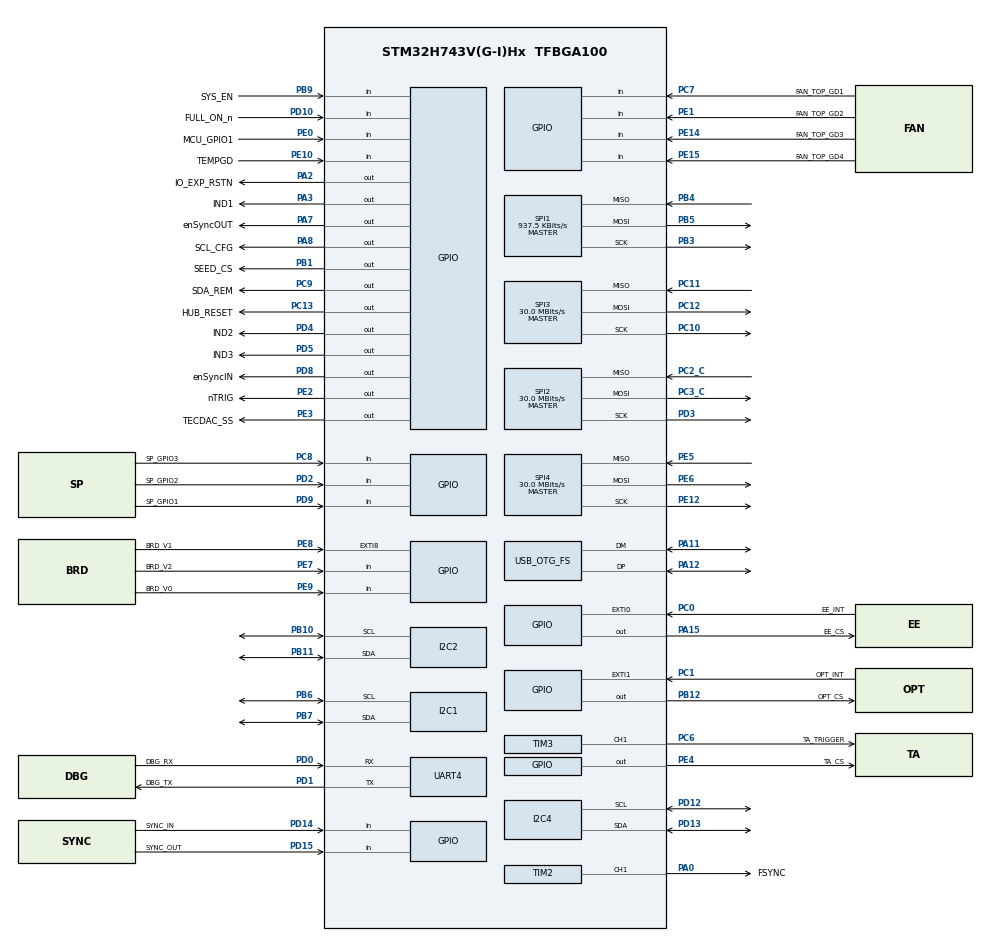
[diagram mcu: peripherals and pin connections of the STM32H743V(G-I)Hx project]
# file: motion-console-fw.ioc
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CORTEX_M7.default_mode_Activation=1
Dma.Request0=UART4_RX
Dma.Request1=UART4_TX
Dma.UART4_RX.0.Direction=DMA_PERIPH_TO_MEMORY
Dma.UART4_RX.0.EventEnable=DISABLE
Dma.UART4_RX.0.FIFOMode=DMA_FIFOMODE_DISABLE
Dma.UART4_RX.0.Instance=DMA1_Stream0
Dma.UART4_RX.0.MemDataAlignment=DMA_MDATAALIGN_BYTE
Dma.UART4_RX.0.MemInc=DMA_MINC_ENABLE
Dma.UART4_RX.0.Mode=DMA_NORMAL
Dma.UART4_RX.0.PeriphDataAlignment=DMA_PDATAALIGN_BYTE
Dma.UART4_RX.0.PeriphInc=DMA_PINC_DISABLE
Dma.UART4_RX.0.Polarity=HAL_DMAMUX_REQ_GEN_RISING
Dma.UART4_RX.0.Priority=DMA_PRIORITY_LOW
Dma.UART4_RX.0.RequestNumber=1
Dma.UART4_RX.0.SignalID=NONE
Dma.UART4_RX.0.SyncEnable=DISABLE
Dma.UART4_RX.0.SyncPolarity=HAL_DMAMUX_SYNC_NO_EVENT
Dma.UART4_RX.0.SyncRequestNumber=1
Dma.UART4_RX.0.SyncSignalID=NONE
Dma.UART4_TX.1.Direction=DMA_MEMORY_TO_PERIPH
Dma.UART4_TX.1.EventEnable=DISABLE
Dma.UART4_TX.1.FIFOMode=DMA_FIFOMODE_DISABLE
Dma.UART4_TX.1.Instance=DMA1_Stream1
Dma.UART4_TX.1.MemDataAlignment=DMA_MDATAALIGN_BYTE
Dma.UART4_TX.1.MemInc=DMA_MINC_ENABLE
Dma.UART4_TX.1.Mode=DMA_NORMAL
Dma.UART4_TX.1.PeriphDataAlignment=DMA_PDATAALIGN_BYTE
Dma.UART4_TX.1.PeriphInc=DMA_PINC_DISABLE
Dma.UART4_TX.1.Polarity=HAL_DMAMUX_REQ_GEN_RISING
Dma.UART4_TX.1.Priority=DMA_PRIORITY_LOW
Dma.UART4_TX.1.RequestNumber=1
Dma.UART4_TX.1.SignalID=NONE
Dma.UART4_TX.1.SyncEnable=DISABLE
Dma.UART4_TX.1.SyncPolarity=HAL_DMAMUX_SYNC_NO_EVENT
Dma.UART4_TX.1.SyncRequestNumber=1
Dma.UART4_TX.1.SyncSignalID=NONE
I2C1.Timing=0x10B71B27
I2C2.Timing=0x107075B0
I2C4.Timing=0x107075B0
Mcu.Family=STM32H7
Mcu.Name=STM32H743V(G-I)Hx
Mcu.Package=TFBGA100
NVIC.DMA1_Stream0_IRQn=true\:0\:0\:false\:false\:true\:false\:true\:true
NVIC.DMA1_Stream1_IRQn=true\:0\:0\:false\:false\:true\:false\:true\:true
NVIC.I2C1_ER_IRQn=true\:0\:0\:false\:false\:true\:true\:true\:true
NVIC.I2C1_EV_IRQn=true\:0\:0\:false\:false\:true\:true\:true\:true
NVIC.I2C2_ER_IRQn=true\:0\:0\:false\:false\:true\:true\:true\:true
NVIC.I2C2_EV_IRQn=true\:0\:0\:false\:false\:true\:true\:true\:true
NVIC.I2C4_ER_IRQn=true\:0\:0\:false\:false\:true\:true\:true\:true
NVIC.I2C4_EV_IRQn=true\:0\:0\:false\:false\:true\:true\:true\:true
NVIC.OTG_FS_IRQn=true\:0\:0\:false\:false\:true\:false\:true\:true
NVIC.PriorityGroup=NVIC_PRIORITYGROUP_4
NVIC.SPI1_IRQn=true\:0\:0\:false\:false\:true\:true\:true\:true
NVIC.TIM15_IRQn=true\:0\:0\:false\:false\:true\:true\:true\:true
NVIC.TIM17_IRQn=true\:15\:0\:false\:false\:true\:false\:true\:true
NVIC.TIM2_IRQn=true\:0\:0\:false\:false\:true\:true\:true\:true
NVIC.TIM3_IRQn=true\:0\:0\:false\:false\:true\:true\:true\:true
NVIC.TIM4_IRQn=true\:0\:0\:false\:false\:true\:true\:true\:true
NVIC.TIM8_BRK_TIM12_IRQn=true\:0\:0\:false\:false\:true\:true\:true\:true
NVIC.TIM8_CC_IRQn=true\:0\:0\:false\:false\:true\:true\:true\:true
NVIC.TIM8_TRG_COM_TIM14_IRQn=true\:0\:0\:false\:false\:true\:true\:true\:true
NVIC.TIM8_UP_TIM13_IRQn=true\:0\:0\:false\:false\:true\:true\:true\:true
NVIC.TimeBase=TIM17_IRQn
NVIC.TimeBaseIP=TIM17
NVIC.UART4_IRQn=true\:0\:0\:false\:false\:true\:true\:true\:true
PA0.GPIO_Label=FSYNC
PA0.Signal=S_TIM2_CH1_ETR
PA11.Mode=Device_Only
PA11.Signal=USB_OTG_FS_DM
PA12.Mode=Device_Only
PA12.Signal=USB_OTG_FS_DP
PA13\ (JTMS/SWDIO).Mode=Serial_Wire
PA13\ (JTMS/SWDIO).Signal=DEBUG_JTMS-SWDIO
PA14\ (JTCK/SWCLK).Mode=Serial_Wire
PA14\ (JTCK/SWCLK).Signal=DEBUG_JTCK-SWCLK
PA15\ (JTDI).GPIO_Label=EE_CS
PA15\ (JTDI).PinState=GPIO_PIN_SET
PA15\ (JTDI).Signal=GPIO_Output
PA2.GPIO_Label=IO_EXP_RSTN
PA2.PinState=GPIO_PIN_SET
PA2.Signal=GPIO_Output
PA3.GPIO_Label=IND1
PA3.PinState=GPIO_PIN_SET
PA3.Signal=GPIO_Output
PA7.GPIO_Label=enSyncOUT
PA7.PinState=GPIO_PIN_SET
PA7.Signal=GPIO_Output
PA8.GPIO_Label=SCL_CFG
PA8.Signal=GPIO_Output
PB1.GPIO_Label=SEED_CS
PB1.PinState=GPIO_PIN_SET
PB1.Signal=GPIO_Output
PB10.Mode=I2C
PB10.Signal=I2C2_SCL
PB11.Mode=I2C
PB11.Signal=I2C2_SDA
PB12.GPIO_Label=OPT_CS
PB12.PinState=GPIO_PIN_SET
PB12.Signal=GPIO_Output
PB3\ (JTDO/TRACESWO).Mode=Full_Duplex_Master
PB3\ (JTDO/TRACESWO).Signal=SPI1_SCK
PB4\ (NJTRST).Mode=Full_Duplex_Master
PB4\ (NJTRST).Signal=SPI1_MISO
PB5.Mode=Full_Duplex_Master
PB5.Signal=SPI1_MOSI
PB6.Mode=I2C
PB6.Signal=I2C1_SCL
PB7.Mode=I2C
PB7.Signal=I2C1_SDA
PB9.GPIO_Label=SYS_EN
PB9.Signal=GPIO_Input
PC0.GPIO_Label=EE_INT
PC0.Signal=GPXTI0
PC1.GPIO_Label=OPT_INT
PC1.Signal=GPXTI1
PC10.Mode=Full_Duplex_Master
PC10.Signal=SPI3_SCK
PC11.Mode=Full_Duplex_Master
PC11.Signal=SPI3_MISO
PC12.Mode=Full_Duplex_Master
PC12.Signal=SPI3_MOSI
PC13.GPIO_Label=HUB_RESET
PC13.Signal=GPIO_Output
PC2_C.Mode=Full_Duplex_Master
PC2_C.Signal=SPI2_MISO
PC3_C.Mode=Full_Duplex_Master
PC3_C.Signal=SPI2_MOSI
PC6.GPIO_Label=TA_TRIGGER
PC6.Signal=S_TIM3_CH1
PC7.GPIO_Label=FAN_TOP_GD1
PC7.Signal=GPIO_Input
PC8.GPIO_Label=SP_GPIO3
PC8.Signal=GPIO_Input
PC9.GPIO_Label=SDA_REM
PC9.Signal=GPIO_Output
PD0.GPIO_Label=DBG_RX
PD0.Mode=Asynchronous
PD0.Signal=UART4_RX
PD1.GPIO_Label=DBG_TX
PD1.Mode=Asynchronous
PD1.Signal=UART4_TX
PD10.GPIO_Label=FULL_ON_n
PD10.Signal=GPIO_Input
PD12.Mode=I2C
PD12.Signal=I2C4_SCL
PD13.Mode=I2C
PD13.Signal=I2C4_SDA
PD14.GPIO_Label=SYNC_IN
PD14.Signal=GPIO_Input
PD15.GPIO_Label=SYNC_OUT
PD15.Signal=GPIO_Input
PD2.GPIO_Label=SP_GPIO2
PD2.Signal=GPIO_Input
PD3.Mode=Full_Duplex_Master
PD3.Signal=SPI2_SCK
PD4.GPIO_Label=IND2
PD4.PinState=GPIO_PIN_SET
PD4.Signal=GPIO_Output
PD5.GPIO_Label=IND3
PD5.PinState=GPIO_PIN_SET
PD5.Signal=GPIO_Output
PD8.GPIO_Label=enSyncIN
PD8.Signal=GPIO_Output
PD9.GPIO_Label=SP_GPIO1
PD9.Signal=GPIO_Input
PE0.GPIO_Label=MCU_GPIO1
PE0.Signal=GPIO_Input
PE1.GPIO_Label=FAN_TOP_GD2
PE1.Signal=GPIO_Input
PE10.GPIO_Label=TEMPGD
PE10.Signal=GPIO_Input
PE12.Mode=Full_Duplex_Master
PE12.Signal=SPI4_SCK
PE14.GPIO_Label=FAN_TOP_GD3
PE14.Signal=GPIO_Input
PE15.GPIO_Label=FAN_TOP_GD4
PE15.Signal=GPIO_Input
PE2.GPIO_Label=nTRIG
PE2.PinState=GPIO_PIN_SET
PE2.Signal=GPIO_Output
PE3.GPIO_Label=TECDAC_SS
PE3.PinState=GPIO_PIN_SET
PE3.Signal=GPIO_Output
PE4.GPIO_Label=TA_CS
PE4.PinState=GPIO_PIN_SET
PE4.Signal=GPIO_Output
PE5.Mode=Full_Duplex_Master
PE5.Signal=SPI4_MISO
PE6.Mode=Full_Duplex_Master
PE6.Signal=SPI4_MOSI
PE7.GPIO_Label=BRD_V2
PE7.Signal=GPIO_Input
PE8.GPIO_Label=BRD_V1
PE8.Signal=GPXTI8
PE9.GPIO_Label=BRD_V0
PE9.Signal=GPIO_Input
PH0-OSC_IN\ (PH0).Mode=HSE-External-Oscillator
PH0-OSC_IN\ (PH0).Signal=RCC_OSC_IN
PH1-OSC_OUT\ (PH1).Mode=HSE-External-Oscillator
PH1-OSC_OUT\ (PH1).Signal=RCC_OSC_OUT
ProjectManager.HeapSize=0x200
ProjectManager.StackSize=0x400
ProjectManager.TargetToolchain=CMake
RCC.ADCFreq_Value=480000000
RCC.APB1Freq_Value=120000000
RCC.APB2Freq_Value=120000000
RCC.APB3Freq_Value=120000000
RCC.APB4Freq_Value=120000000
RCC.CortexFreq_Value=240000000
RCC.DIVM1=3
RCC.DIVM2=3
RCC.DIVM3=3
RCC.DIVN1=120
RCC.DIVN2=120
RCC.DIVN3=120
RCC.DIVP1=4
RCC.DIVQ1=16
RCC.DIVQ2=16
RCC.DIVQ3=16
RCC.DIVR1=16
RCC.DIVR3=16
RCC.HCLKFreq_Value=120000000
RCC.HPRE=RCC_HCLK_DIV2
RCC.HSE_VALUE=24000000
RCC.I2C123CLockSelection=RCC_I2C123CLKSOURCE_PLL3
RCC.I2C4CLockSelection=RCC_I2C4CLKSOURCE_PLL3
RCC.LPTIM1CLockSelection=RCC_LPTIM1CLKSOURCE_PLL3
RCC.PLLSourceVirtual=RCC_PLLSOURCE_HSE
RCC.RNGCLockSelection=RCC_RNGCLKSOURCE_PLL
RCC.SYSCLKFreq_VALUE=240000000
RCC.SYSCLKSource=RCC_SYSCLKSOURCE_PLLCLK
RCC.Spi45ClockSelection=RCC_SPI45CLKSOURCE_PLL2
RCC.USART234578CLockSelection=RCC_USART234578CLKSOURCE_PLL2
RCC.USBCLockSelection=RCC_USBCLKSOURCE_HSI48
RCC.USBFreq_Value=48000000
SH.S_TIM2_CH1_ETR.0=TIM2_CH1,PWM Generation1 CH1
SH.S_TIM3_CH1.0=TIM3_CH1,PWM Generation1 CH1
SPI1.BaudRatePrescaler=SPI_BAUDRATEPRESCALER_64
SPI1.CLKPhase=SPI_PHASE_2EDGE
SPI1.CalculateBaudRate=937.5 KBits/s
SPI1.DataSize=SPI_DATASIZE_8BIT
SPI1.Direction=SPI_DIRECTION_2LINES
SPI1.FirstBit=SPI_FIRSTBIT_MSB
SPI1.Mode=SPI_MODE_MASTER
SPI1.NSSPMode=SPI_NSS_PULSE_DISABLE
SPI1.VirtualType=VM_MASTER
SPI2.CalculateBaudRate=30.0 MBits/s
SPI2.Direction=SPI_DIRECTION_2LINES
SPI2.Mode=SPI_MODE_MASTER
SPI2.VirtualType=VM_MASTER
SPI3.CalculateBaudRate=30.0 MBits/s
SPI3.Direction=SPI_DIRECTION_2LINES
SPI3.Mode=SPI_MODE_MASTER
SPI3.VirtualType=VM_MASTER
SPI4.CalculateBaudRate=30.0 MBits/s
SPI4.Direction=SPI_DIRECTION_2LINES
SPI4.Mode=SPI_MODE_MASTER
SPI4.VirtualType=VM_MASTER
TIM12.Period=25000-1
TIM12.Prescaler=120-1
TIM15.Period=8000-1
TIM15.Prescaler=1200-1
TIM2.Channel-PWM\ Generation1\ CH1=TIM_CHANNEL_1
TIM2.Period=25000-1
TIM2.Prescaler=120-1
TIM2.Pulse-PWM\ Generation1\ CH1=1000
TIM2.TIM_MasterOutputTrigger=TIM_TRGO_UPDATE
TIM3.Channel-PWM\ Generation1\ CH1=TIM_CHANNEL_1
TIM3.OCPolarity_1=TIM_OCPOLARITY_LOW
TIM3.Period=1250-1
TIM3.Prescaler=120-1
TIM3.Pulse-PWM\ Generation1\ CH1=250
TIM4.Period=2500-1
TIM4.Prescaler=12000-1
TIM8.Period=2500-1
TIM8.Prescaler=12000-1
USB_DEVICE.CLASS_NAME_FS=CDC
USB_DEVICE.PID_CDC_FS=0xA53E
USB_DEVICE.VID-CDC_FS=0x483
USB_DEVICE.VirtualMode-CDC_FS=Cdc
USB_DEVICE.VirtualModeFS=Cdc_FS
USB_OTG_FS.VirtualMode=Device_Only
VP_CRC_VS_CRC.Mode=CRC_Activate
VP_IWDG1_VS_IWDG.Mode=IWDG_Activate
VP_MEMORYMAP_VS_MEMORYMAP.Mode=CurAppReg
VP_RNG_VS_RNG.Mode=RNG_Activate
VP_SYS_VS_tim17.Mode=TIM17
VP_TIM12_VS_ClockSourceINT.Mode=Internal
VP_TIM15_VS_ClockSourceINT.Mode=Internal
VP_TIM1_VS_ClockSourceINT.Mode=Internal
VP_TIM2_VS_ClockSourceINT.Mode=Internal
VP_TIM3_VS_ClockSourceINT.Mode=Internal
VP_TIM3_VS_ClockSourceITR.Mode=TriggerSource_ITR1
VP_TIM3_VS_ControllerModeTrigger.Mode=Trigger Mode
VP_TIM3_VS_OPM.Mode=OPM_bit
VP_TIM4_VS_ClockSourceINT.Mode=Internal
VP_TIM8_VS_ClockSourceINT.Mode=Internal
VP_USB_DEVICE_VS_USB_DEVICE_CDC_FS.Mode=CDC_FS
board=custom

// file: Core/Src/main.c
/* USER CODE BEGIN Header */
/**
  ******************************************************************************
  * @file           : main.c
  * @brief          : Main program body
  ******************************************************************************
  * @attention
  *
  * Copyright (c) 2025 STMicroelectronics.
  * All rights reserved.
  *
  * This software is licensed under terms that can be found in the LICENSE file
  * in the root directory of this software component.
  * If no LICENSE file comes with this software, it is provided AS-IS.
  *
  ******************************************************************************
  */
 #include "version.h"
/* USER CODE END Header */
#include "main.h"
#include "usb_device.h"

/* USER CODE BEGIN Includes */
#include "usb_recovery.h"
#include "logging.h"
#include "usbd_cdc_if.h"
#include "uart_comms.h"
#include "trigger.h"
#include "pdc_poll.h"
#include "led_driver.h"
#include "tca9548a.h"
#include "console_i2c_health.h"
#include "pca9535.h"
#include "ads7828.h"
#include "ads7924.h"
#include "fan_driver.h"
#include "ad5761r.h"
#include "XO2_dev.h"
#include "XO2_api.h"
#include "XO2_cmds.h"
#include "fpga_attest.h"
#include "safety_envelope.h"
#include "safety_ufm_record.h"
#include "motion_cfg_keys.h"

/* Bus time per main-loop iteration given to the FPGA attestation readback
 * (about 5 configuration pages at 100 kHz). Keeps command latency and the
 * 25 ms telemetry cadence within their budgets while the check runs. */
#define FPGA_ATTEST_BUDGET_MS 12U
#include "if_fpga_prog.h"
#include "motion_config.h"
#include "fpga_register_map.h"
#include "jsmn.h"
#include "utils.h"
#include "msg_queue.h"
#include "odometer.h"
#include "console_serial.h"

#include <stdio.h>
#include <string.h>
#include <stdbool.h>
#include <stdlib.h>

/* USER CODE END Includes */

/* USER CODE BEGIN PD */

// #define SCAN_DISPLAY

/* USER CODE END PD */

CRC_HandleTypeDef hcrc;

I2C_HandleTypeDef hi2c1;
I2C_HandleTypeDef hi2c2;
I2C_HandleTypeDef hi2c4;

IWDG_HandleTypeDef hiwdg1;

RNG_HandleTypeDef hrng;

SPI_HandleTypeDef hspi1;
SPI_HandleTypeDef hspi2;
SPI_HandleTypeDef hspi3;
SPI_HandleTypeDef hspi4;

TIM_HandleTypeDef htim1;
TIM_HandleTypeDef htim2;
TIM_HandleTypeDef htim3;
TIM_HandleTypeDef htim4;
TIM_HandleTypeDef htim8;
TIM_HandleTypeDef htim12;
TIM_HandleTypeDef htim15;

UART_HandleTypeDef huart4;
DMA_HandleTypeDef hdma_uart4_rx;
DMA_HandleTypeDef hdma_uart4_tx;

/* USER CODE BEGIN PV */

uint8_t rxBuffer[COMMAND_MAX_SIZE];
uint8_t txBuffer[COMMAND_MAX_SIZE];

// Declare handles for your two multiplexers
extern TCA9548A_HandleTypeDef iic_mux[2];
extern ADS7828_HandleTypeDef adc_mon[2];
ADS7924_HandleTypeDef tec_ads;
extern bool ad5761r_enabled;
extern FAN_Driver fan;
static MachXO_Handle_t s_xo2_i2c_handle;
static XO2Handle_t     s_xo2_handle;

double TEC_TRIP_VALUE = 0.0;
double OPT_GAIN_VALUE = 0.0;
uint16_t OPT_THRESH_VALUE = 0;
double EE_GAIN_VALUE = 0.0;
uint16_t EE_THRESH_VALUE = 0;

ad5761r_dev tec_dac;

volatile bool _enter_dfu = false;

/* USER CODE END PV */

void SystemClock_Config(void);
void PeriphCommonClock_Config(void);
static void MPU_Config(void);
static void MX_GPIO_Init(void);
static void MX_DMA_Init(void);
static void MX_CRC_Init(void);
static void MX_I2C1_Init(void);
static void MX_I2C2_Init(void);
static void MX_RNG_Init(void);
static void MX_UART4_Init(void);
static void MX_TIM1_Init(void);
static void MX_TIM3_Init(void);
static void MX_TIM12_Init(void);
static void MX_TIM15_Init(void);
static void MX_I2C4_Init(void);
static void MX_TIM2_Init(void);
static void MX_SPI1_Init(void);
static void MX_SPI2_Init(void);
static void MX_SPI3_Init(void);
static void MX_SPI4_Init(void);
static void MX_TIM8_Init(void);
static void MX_TIM4_Init(void);
static void MX_IWDG1_Init(void);
/* USER CODE BEGIN PFP */

#ifdef SCAN_DISPLAY
static uint8_t I2C_scan(I2C_HandleTypeDef * pI2c, uint8_t* addr_list, size_t list_size, bool display) {

	uint8_t found = 0;

    // Iterate through all possible 7-bit addresses
    for (uint8_t address = 0x00; address <= 0x7F; address++) {
        HAL_StatusTypeDef status;
        watchdog_refresh(); /* up to 128 x 50 ms on a stuck bus */
        status = HAL_I2C_IsDeviceReady(pI2c, address << 1, 2, 50); // Address shift left by 1 for read/write bit
        if (status == HAL_OK) {
        	if(addr_list != NULL && found < list_size) {
        		addr_list[found] = address;
        	}
        	found++;
        	if(display)
        	{
        		printf("%2x ", address);
        	}
        }else{
        	if(display)
        	{
        		printf("-- ");
        	}
        }
        if (display && (address + 1) % 16 == 0)  printf("\r\n");
    }

	if(display)
	{
		printf("\r\n");
	    fflush(stdout);
	}

    return found;
}
#endif

/*
 * Clear the bootloader's failsafe boot counter (RTC->BKP6R).
 * The secure bootloader increments BKP6R on every launch attempt and arms the
 * IWDG before jumping here; after BL_BOOT_FAIL_MAX consecutive attempts that do
 * not clear it, the bootloader enters USB DFU instead of launching us. Calling
 * this once we have fully initialized signals a successful boot, so the next
 * normal reset starts from a clean count.
 *
 * The HAL RTC module is not enabled in this build, so access the backup domain
 * directly via CMSIS (same sequence used for the DFU request in main()'s loop).
 */
static void clear_boot_counter(void)
{
  PWR->CR1     |= PWR_CR1_DBP;            /* disable backup-domain write protect  */
  RCC->APB4ENR |= RCC_APB4ENR_RTCAPBEN;  /* RTC register APB interface clock      */
  RCC->CSR     |= RCC_CSR_LSION;          /* LSI on (RTC kernel clock source)      */
  { uint32_t to = 0U;
    while (((RCC->CSR & RCC_CSR_LSIRDY) == 0U) && (++to < 0x00100000U)) { } }
  if ((RCC->BDCR & RCC_BDCR_RTCSEL) == 0U) {
    RCC->BDCR = (RCC->BDCR & ~RCC_BDCR_RTCSEL) | RCC_BDCR_RTCSEL_1; /* LSI */
  }
  RCC->BDCR |= RCC_BDCR_RTCEN;            /* enable RTC                            */
  RTC->BKP6R = 0U;                        /* successful boot: reset the attempt count */
  __DSB();
}

void configure_pin_as_gpio_output(GPIO_TypeDef* GPIOx, uint16_t GPIO_Pin) {
    GPIO_InitTypeDef GPIO_InitStruct = {0};

    // 1. Enable the GPIO clock
    if (GPIOx == GPIOA) __HAL_RCC_GPIOA_CLK_ENABLE();
    else if (GPIOx == GPIOB) __HAL_RCC_GPIOB_CLK_ENABLE();
    else if (GPIOx == GPIOC) __HAL_RCC_GPIOC_CLK_ENABLE();
    // Add other GPIO ports as needed

    // 2. Configure the pin
    GPIO_InitStruct.Pin = GPIO_Pin;
    GPIO_InitStruct.Mode = GPIO_MODE_OUTPUT_PP;  // Push-pull output
    // GPIO_InitStruct.Mode = GPIO_MODE_OUTPUT_OD; // For open-drain output
    GPIO_InitStruct.Pull = GPIO_NOPULL;          // No pull-up or pull-down
    GPIO_InitStruct.Speed = GPIO_SPEED_FREQ_LOW; // Or MEDIUM/HIGH/VERY_HIGH

    HAL_GPIO_Init(GPIOx, &GPIO_InitStruct);
}

void delay_ms(uint32_t ms)
{
    uint32_t delay_cycles = (SystemCoreClock / 1000) * ms;
    while (delay_cycles--) {
        __NOP();  // Ensures the loop doesn't get optimized away
    }
}

/* Refresh the independent watchdog (250 ms window, CFW-01). A no-op before
 * MX_IWDG1_Init(). Call it only from bounded waits; Error_Handler() and the
 * fault handlers must never refresh it. */
void watchdog_refresh(void)
{
    if (hiwdg1.Instance != NULL) {
        (void)HAL_IWDG_Refresh(&hiwdg1);
    }
}

/* HAL_Delay() that keeps the watchdog refreshed, for the boot delays and the
 * FPGA programming waits (XO2 erase takes seconds). */
void delay_ms_wdg(uint32_t ms)
{
    uint32_t start = HAL_GetTick();

    watchdog_refresh();
    while ((HAL_GetTick() - start) < ms) {
        HAL_Delay(1);
        watchdog_refresh();
    }
}

/* USER CODE END PFP */

/* USER CODE BEGIN 0 */

/* ---- Safety parameters and the laser operating point --------------------
 * (PTR-2026-1-5 host-writable safety state; CFW-10; SDD ARCH-125/ARCH-83)
 *
 * Two kinds of register load, in this order, at boot, after every host
 * configuration write and after every completed FPGA attestation:
 *
 *   1. The SAFETY LOADS: the EE/OPT limit registers from the per-unit
 *      safety record in each safety FPGA's UFM (safety_ufm_record.h, bounded
 *      by safety_envelope.h), and the fixed TA / seed driver clamps of
 *      safety_envelope.h. No host data takes part. A device without a valid
 *      record gets no limit loads: its registers keep the design reset
 *      values, and the attestation interlock keeps the laser off.
 *   2. The OPERATIONAL point from the stored configuration record:
 *      TA_CURRENT_DRV, TA_PULSE_WIDTH, SEED_CW_GAIN, SEED_DDS_GAIN, each
 *      range-checked against the envelope; TA_PULSE_WIDTH is also lowered by
 *      the unit's record (motion_cfg_set_unit_ceiling: the ceiling applies to host config
 *      writes and to the I2C pass-through). Safety keys and unknown keys in
 *      the record are ignored and logged (they cannot be stored by this
 *      firmware; see motion_config.c).
 *
 * Every register is written and read back. Any failure is reported to the
 * host and refuses Trigger_Start() (TRIG_INTERLOCK_LIMITS) until a later
 * apply succeeds. The SDK used to write the same registers at connection
 * through OW_CTRL_I2C_WR; in a Release build those writes are now refused
 * for the safety-owned registers (fpga_register_map.c). */

static bool     s_limits_fault;
static unsigned s_limits_fail_count;
static char     s_limits_first_fail[56];

bool motion_cfg_limits_fault(void)
{
    return s_limits_fault;
}

static void limits_fail(const char *key, const char *why)
{
    printf("ERROR: %s not applied: %s\r\n", key, why);
    if (s_limits_fail_count == 0U) {
        (void)snprintf(s_limits_first_fail, sizeof(s_limits_first_fail), "%s: %s", key, why);
    }
    s_limits_fail_count++;
    s_limits_fault = true;
}

/* Write a register and read it back; NULL on success, else the reason. */
static const char *fpga_write_verify(const FpgaRegister *reg, const uint8_t *data)
{
    uint8_t rb[4] = {0, 0, 0, 0};

    if (TCA9548A_Write_Data(reg->muxIdx, reg->channel, reg->i2cAddr,
                            reg->offset, reg->data_len, (uint8_t *)data) != TCA9548A_OK) {
        return "write failed";
    }
    if (TCA9548A_Read_Data(reg->muxIdx, reg->channel, reg->i2cAddr,
                           reg->offset, reg->data_len, rb) != TCA9548A_OK) {
        return "read-back failed";
    }
    if (memcmp(rb, data, reg->data_len) != 0) {
        return "read-back mismatch";
    }
    return NULL;
}

/* Write a raw little-endian register value and read it back. */
static bool fpga_write_raw(const char *name, uint32_t raw)
{
    const FpgaRegister *reg = fpga_register_lookup(name);
    if (reg == NULL || reg->direction != FPGA_DIR_RW || reg->data_len == 0U || reg->data_len > 4U) {
        limits_fail(name, "not a settable register");
        return false;
    }
    if (reg->data_len < 4U && raw > ((1UL << (8U * reg->data_len)) - 1UL)) {
        limits_fail(name, "too large for the register");
        return false;
    }
    uint8_t data_buf[4] = {0, 0, 0, 0};
    for (uint8_t b = 0; b < reg->data_len; b++) {
        data_buf[b] = (uint8_t)((raw >> (8u * b)) & 0xFFu);
    }
    const char *why = fpga_write_verify(reg, data_buf);
    if (why != NULL) {
        limits_fail(name, why);
        return false;
    }
    return true;
}

/* 1. The safety loads (see above), and the unit's ceilings for the
 *    operating point. */
static void apply_safety_loads(void)
{
    const safety_ufm_limits_t *ee  = fpga_attest_ufm_limits((uint8_t)MUX_FPGA_SAFE_EE);
    const safety_ufm_limits_t *opt = fpga_attest_ufm_limits((uint8_t)MUX_FPGA_SAFE_OPT);
    safety_reg_load_t loads[SAFETY_REG_LOADS_MAX];
    size_t n = safety_reg_loads(ee, opt, loads, SAFETY_REG_LOADS_MAX);

    if (ee == NULL || opt == NULL) {
#if defined(OW_FACTORY_PROGRAMMING)
        printf("Safety record: EE %s, OPT %s; a device without one keeps its design limits until the stored configuration's safety keys override them (Factory image)\r\n",
               ee ? "valid" : "none", opt ? "valid" : "none");
#else
        printf("Safety record: EE %s, OPT %s; a device without one keeps its design limits and the laser stays interlocked\r\n",
               ee ? "valid" : "none", opt ? "valid" : "none");
#endif
    }
    motion_cfg_set_unit_ceiling("TA_PULSE_WIDTH", safety_ta_pulse_width_max_us(ee, opt));
    for (size_t i = 0; i < n; i++) {
        if (fpga_write_raw(loads[i].reg, loads[i].raw)) {
            printf("Safety %s -> raw=0x%08lX, verified%s\r\n", loads[i].reg,
                   (unsigned long)loads[i].raw, loads[i].per_unit ? " (per-unit record)" : "");
        }
    }
}

/* Read a little-endian register of up to 4 bytes through the register map. */
static bool fpga_read_u32(const char *key, uint32_t *out)
{
    const FpgaRegister *reg = fpga_register_lookup(key);
    uint8_t b[4] = {0, 0, 0, 0};

    if (reg == NULL || reg->data_len > 4U ||
        TCA9548A_Read_Data(reg->muxIdx, reg->channel, reg->i2cAddr, reg->offset,
                           reg->data_len, b) != TCA9548A_OK) {
        return false;
    }
    *out = (uint32_t)b[0] | ((uint32_t)b[1] << 8) | ((uint32_t)b[2] << 16) | ((uint32_t)b[3] << 24);
    return true;
}

/* The pulse-width lower limit must not exceed the upper limit. */
static void check_pulse_width_order(const char *ll_key, const char *ul_key)
{
    uint32_t ll = 0U, ul = 0U;

    if (!fpga_read_u32(ll_key, &ll) || !fpga_read_u32(ul_key, &ul)) {
        limits_fail(ul_key, "read-back failed");
    } else if (ll > ul) {
        limits_fail(ll_key, "above the upper limit");
    }
}

/* After an apply: report a limits fault to the host and stop a running
 * trigger. Trigger_Start() refuses while it is set. */
static void report_limits_state(void)
{
    if (!s_limits_fault) {
        return;
    }
    char m[MQ_MAX_MSG_SIZE];
    /* Compact so the longest key + reason still fits one queue slot
     * (MQ_MAX_MSG_SIZE); the first failure is named, the count covers all. */
    int n = snprintf(m, sizeof(m),
                     "{\"type\":\"system\",\"state\":\"error\",\"msg\":\"safety limit not applied\",\"key\":\"%.40s\",\"count\":%u}",
                     s_limits_first_fail, s_limits_fail_count);
    if (n > 0 && (size_t)n < sizeof(m)) {
        (void)mq_push(m, (size_t)n);
    }
    (void)Trigger_Stop();
}

/* TEC thermal trip threshold, from a temperature in degrees C. No logging:
 * it runs before the UART exists (see safety_envelope_init). */
static double s_tec_trip_c;
static void tec_trip_set_c(double trip_c)
{
    s_tec_trip_c = trip_c;
    TEC_TRIP_VALUE = solve_v(temperature_to_resistance(trip_c));
}

/* The compile-time safety parameters, in force from reset: called first
 * thing in main(), before any peripheral and before the configuration
 * record is read, so the thermal trip is armed whatever the record holds.
 * Nothing here may print or touch a peripheral: _write() on the
 * uninitialised debug UART ends in Error_Handler(). */
static void safety_envelope_init(void)
{
    tec_trip_set_c(SAFETY_TEC_TRIP_C);
}

/* 2. One operational key of the stored record. */
static void apply_operational_setting(const cfg_key_rule_t *rule, const char *keybuf, double val)
{
    double min = rule->min;
    double max = motion_cfg_effective_max(rule);   /* lowered by the unit's record (apply_safety_loads) */
    if (!isfinite(val) || val < min || val > max) {
        limits_fail(keybuf, "out of range");
        return;
    }
    if (rule->reg == NULL) {
        return;
    }
    uint32_t raw = safety_eng_to_raw(rule->reg, val);
    if (fpga_write_raw(rule->reg, raw)) {
        printf("Wrote %s -> raw=0x%08lX, verified\r\n", keybuf, (unsigned long)raw);
    }
}

#if defined(OW_FACTORY_PROGRAMMING)
/* Factory build only: a safety key in the stored record overrides the
 * firmware value, within the hard bounds, for bench and calibration work.
 * Applied after the safety loads, so it wins. */
static void apply_factory_override(const cfg_key_rule_t *rule, const char *keybuf, double val)
{
    if (!isfinite(val) || val < rule->min || val > rule->max) {
        limits_fail(keybuf, "override out of bounds");
        return;
    }
    printf("FACTORY override %s = %.3f\r\n", keybuf, val);
    if (strcmp(keybuf, "TEC_TRIP") == 0) {
        tec_trip_set_c(val);
    } else if (rule->reg != NULL) {
        (void)fpga_write_raw(rule->reg, safety_eng_to_raw(rule->reg, val));
    }
}
#endif

/* Copy one token's text into dst (NUL-terminated, truncated to fit). */
static void cfg_copy_token(char *dst, size_t dst_size, const char *json, const jsmntok_t *t)
{
    int len = t->end - t->start;
    int copy_len = (len < (int)dst_size - 1) ? len : (int)dst_size - 1;

    memcpy(dst, json + t->start, (size_t)copy_len);
    dst[copy_len] = '\0';
}

/* Apply one "key": value pair of the stored record by its class. */
static void cfg_apply_pair(const char *json, const jsmntok_t *key, const jsmntok_t *val)
{
    char keybuf[40];
    cfg_copy_token(keybuf, sizeof(keybuf), json, key);

    const cfg_key_rule_t *rule = motion_cfg_key_rule(keybuf);
    if (rule == NULL) {
        printf("%s: unknown key in the stored config, ignored\r\n", keybuf);
        return;
    }
    if (rule->cls == CFG_KEY_OPAQUE) {
        return;
    }
    double v = 0.0;
    bool is_number = motion_cfg_token_number(json, val, &v);
    if (rule->cls == CFG_KEY_SAFETY) {
#if defined(OW_FACTORY_PROGRAMMING)
        if (is_number) {
            apply_factory_override(rule, keybuf, v);
        } else {
            limits_fail(keybuf, "not a number");
        }
#else
        printf("%s: safety parameter in the stored config ignored (firmware-owned)\r\n", keybuf);
#endif
        return;
    }
    if (!is_number) {
        limits_fail(keybuf, "not a number");
        return;
    }
    apply_operational_setting(rule, keybuf, v);
}

void motion_cfg_apply_settings(void)
{
    const char *json_str = motion_cfg_get_json_ptr();
    if (json_str == NULL) { return; }

    jsmn_parser parser;
    /* Static (not on the stack): the token pool is sized for a full config and
     * is too large to put on the stack of a boot-path function. This routine is
     * only ever called from the single-threaded main loop / command handler. */
    static jsmntok_t tokens[MOTION_CFG_MAX_JSON_TOKENS];
    const unsigned int ntok = (unsigned int)(sizeof(tokens) / sizeof(tokens[0]));

    s_limits_fault = false;
    s_limits_fail_count = 0U;
    s_limits_first_fail[0] = '\0';

    /* 1. Firmware-owned limits first, whatever the record holds. */
    printf("TEC_TRIP %.1f C -> %.3f V (compiled in, in force since reset)\r\n", s_tec_trip_c, TEC_TRIP_VALUE);
    apply_safety_loads();

    /* 2. The operating point from the record. */
    jsmn_init(&parser, NULL);
    int r = jsmn_parse(&parser, json_str, strlen(json_str), tokens, ntok, NULL);
    if (r < 1 || tokens[0].type != JSMN_OBJECT) {
        printf("ERROR: motion config JSON parse failed (jsmn %d); operating point NOT applied\r\n", r);
        const char *msg = "{\"type\": \"system\", \"state\": \"error\", \"msg\": \"motion config parse failed; operating point not applied\"}";
        (void)mq_push(msg, strlen(msg));
        s_limits_fault = true;
    } else {
        int i = 1;
        for (int k = 0; k < tokens[0].size && i + 1 < r; k++) {
            if (tokens[i].type != JSMN_STRING) { break; }
            cfg_apply_pair(json_str, &tokens[i], &tokens[i + 1]);
            i = motion_cfg_skip_token(tokens, r, i + 1);
        }
    }

    check_pulse_width_order("EE_PULSE_WIDTH_LL", "EE_PULSE_WIDTH_UL");
    check_pulse_width_order("OPT_PULSE_WIDTH_LL", "OPT_PULSE_WIDTH_UL");
    report_limits_state();
}

/* USER CODE END 0 */

int main(void)
{

  /* USER CODE BEGIN 1 */
  /* The compile-time safety parameters are in force before anything else
   * runs: the TEC thermal trip threshold no longer depends on the stored
   * configuration record (safety_envelope.h). */
  safety_envelope_init();
  /* USER CODE END 1 */

  /* MPU Configuration--------------------------------------------------------*/
  MPU_Config();

  /* MCU Configuration--------------------------------------------------------*/

  /* Reset of all peripherals, Initializes the Flash interface and the Systick. */
  HAL_Init();

  /* Configure the system clock */
  SystemClock_Config();

  /* Configure the peripherals common clocks */
  PeriphCommonClock_Config();

  /* Initialize all configured peripherals */
  MX_GPIO_Init();
  MX_DMA_Init();
  MX_CRC_Init();
  MX_I2C1_Init();
  MX_I2C2_Init();
  MX_RNG_Init();
  MX_UART4_Init();
  MX_TIM1_Init();
  MX_TIM3_Init();
  MX_TIM12_Init();
  MX_TIM15_Init();
  MX_I2C4_Init();
  MX_TIM2_Init();
  MX_SPI1_Init();
  MX_SPI2_Init();
  MX_SPI3_Init();
  MX_SPI4_Init();
  MX_TIM8_Init();
  MX_TIM4_Init();
  MX_IWDG1_Init();
  /* USER CODE BEGIN 2 */

#if !defined(DEBUG) && !defined(BARE_METAL_BUILD)
  /* Debug port stays closed (PTR-2026-1-5 CON-02, CVE-1191). The secure bootloader
   * reconfigures PA13/PA14 (SWDIO/SWCLK) as plain inputs before launching us (DAP
   * lock). Nothing in this application touches those pins, but assert the state
   * here too so that a bootloader without the lock, or a future GPIO change, can
   * never leave the probe interface live on a Release unit. Analog mode: no
   * input buffer, no pull, lowest leakage. Debug builds keep SWD for development;
   * bare-metal builds have no bootloader in front of them and are not fielded. */
  {
    GPIO_InitTypeDef swd = {0};
    __HAL_RCC_GPIOA_CLK_ENABLE();
    swd.Pin  = GPIO_PIN_13 | GPIO_PIN_14;
    swd.Mode = GPIO_MODE_ANALOG;
    swd.Pull = GPIO_NOPULL;
    HAL_GPIO_Init(GPIOA, &swd);
  }
#endif

  init_dma_logging();

  DWT_Init();

  //HAL_GPIO_DeInit(SCL_CFG_GPIO_Port, SCL_CFG_Pin);
  //HAL_GPIO_DeInit(SDA_REM_GPIO_Port, SDA_REM_Pin);
  HAL_GPIO_WritePin(SCL_CFG_GPIO_Port, SCL_CFG_Pin, GPIO_PIN_RESET);
  HAL_GPIO_WritePin(SDA_REM_GPIO_Port, SDA_REM_Pin, GPIO_PIN_RESET);

  HAL_GPIO_WritePin(IO_EXP_RSTN_GPIO_Port, IO_EXP_RSTN_Pin, GPIO_PIN_RESET);
  HAL_GPIO_WritePin(HUB_RESET_GPIO_Port, HUB_RESET_Pin, GPIO_PIN_RESET);

  // HAL_GPIO_WritePin(SYS_EN_GPIO_Port, SYS_EN_Pin, GPIO_PIN_RESET);

  printf("\033c");
  delay_ms_wdg(250);
  printf("Openwater open-MOTION Console\r\n\r\n");
  printf("FW: %s (%s)\r\nDate: %s\r\n",
       FW_VERSION_STRING,
       FW_SHA_STRING,
       FW_BUILD_TIME_STRING);
  printf("Board Version: 0x%02X\r\n\r\n", BoardV_Read());
#if defined(OW_FACTORY_PROGRAMMING)
  printf("*** FACTORY BUILD: FPGA/UFM programming and safety-parameter overrides are ENABLED.\r\n"
         "*** Manufacturing and RMA bench use only. Not a clinical image.\r\n\r\n");
#endif
  printf("CPU Clock Frequency: %lu MHz\r\n", HAL_RCC_GetSysClockFreq() / 1000000);
  printf("Initializing, please wait ...\r\n");

  // setup fpga the XO2 I2C handle used for FPGA programming
  s_xo2_i2c_handle.hi2c    = &hi2c1;
  s_xo2_i2c_handle.verbose = 0;
  s_xo2_i2c_handle.addr7   = MACHXO_I2C_ADDR_7BIT;
  s_xo2_i2c_handle.mux_idx  = 0;
  s_xo2_i2c_handle.mux_ch  = MUX_FPGA_SEED;

  s_xo2_handle.cfgEn         = TRUE;
  s_xo2_handle.devType       = MachXO2_2000;
  s_xo2_handle.pI2CDrvrCalls = &s_xo2_i2c_handle;
  s_xo2_handle.pfuSecDelay   = delay_us;   /* microsecond delay */
  s_xo2_handle.pfmSecDelay   = delay_ms_wdg; /* millisecond delay; keeps the watchdog refreshed */

  /* Register the handle with the command interface for page-by-page programming */
  if_cmd_set_xo2_prog_handle(&s_xo2_handle);

  // configure TEC DAC
  printf("Initialize TEC DAC\r\n");
  tec_dac.hspi = &hspi1;
  tec_dac.cs_port = TECDAC_SS_GPIO_Port;
  tec_dac.cs_pin = TECDAC_SS_Pin;
  tec_dac.ldac_port=NULL;
  tec_dac.ldac_pin=0;
  tec_dac.clr_port=NULL;
  tec_dac.clr_pin=0;
  tec_dac.rst_port=NULL;
  tec_dac.rst_pin=0;
  tec_dac.type=AD5761R,
  tec_dac.ra=AD5761R_RANGE_M_5V_TO_P_5V;
  tec_dac.pv=AD5761R_SCALE_FULL;
  tec_dac.cv=AD5761R_SCALE_FULL;
  tec_dac.int_ref_en=true;
  tec_dac.exc_temp_sd_en=true;
  tec_dac.b2c_range_en=false;
  tec_dac.ovr_en=false;
  tec_dac.daisy_chain_en=false;

  if(ad5761r_init(&tec_dac) != HAL_OK){
	  printf("Failed to initialize TEC DAC\r\n");
  } else {
	uint16_t val = 0;
	val = volts_to_code(&tec_dac, 0.0f);
    if(ad5761r_write_update_dac_register(&tec_dac, val)){
		printf("TEC DAC Failed to set DAC Voltage\r\n");
	}else{
		printf("TEC DAC Initialized and set DAC Voltage\r\n");
    }
  }

  HAL_GPIO_WritePin(IO_EXP_RSTN_GPIO_Port, IO_EXP_RSTN_Pin, GPIO_PIN_SET);
  // HAL_GPIO_WritePin(SYS_EN_GPIO_Port, SYS_EN_Pin, GPIO_PIN_SET);

  HAL_GPIO_WritePin(enSyncIN_GPIO_Port, enSyncIN_Pin, GPIO_PIN_RESET); // set for internal sync
  HAL_GPIO_WritePin(enSyncOUT_GPIO_Port, enSyncOUT_Pin, GPIO_PIN_SET); // disable fsync output
  HAL_GPIO_WritePin(nTRIG_GPIO_Port, nTRIG_Pin, GPIO_PIN_SET); // disable TA Trigger to fpga

  trigger_init();
  watchdog_refresh();

  // config trigger timers; zero-init so unassigned fields (e.g.
  // LaserPulseSkipDelayUsec) don't inherit stack garbage — a nonzero skip
  // delay inflates the long LSYNC slot and halves the laser rate at boot
  Trigger_Config_t triggerSetup = {0};
  triggerSetup.frequencyHz = 40.0f;
  triggerSetup.triggerPulseWidthUsec = 1000;
  triggerSetup.laserPulseDelayUsec = 250;
  triggerSetup.laserPulseWidthUsec = 1000;
  triggerSetup.EnableSyncOut = false;
  triggerSetup.EnableTaTrigger = true;
  triggerSetup.LaserPulseSkipInterval = 0;
  Trigger_SetConfig(&triggerSetup);

  // HAL_TIM_PWM_Start(&htim3, TIM_CHANNEL_1); // TA Trigger

  LED_RGB_SET(LED_GREEN); // GREEN - starting up

  // Initialize first multiplexer on I2C1 with default address
  for(int i = 0; i < 2; i++)
  {
	  if (TCA9548A_Init(i, i==0?&hi2c1:&hi2c2, TCA9548A_DEFAULT_ADDRESS) != TCA9548A_OK) {
	      printf("Failed to initialize MUX1 on I2C1\r\n");
	      iic_mux[i].initialized = false;
	  } else {
		  printf("Initialized MUX%d\r\n", i+1);
	      iic_mux[i].initialized = true;
	  }

  }

#ifdef SCAN_DISPLAY
  // printf("I2C1\r\n");
  // I2C_scan(&hi2c1, NULL, 0, true);

  //TCA9548A_SelectChannel(1, 0); // scan pdu
  // TCA9548A_SelectChannel(1, 1); // scan temp sensors
  //printf("I2C2\r\n");
  //I2C_scan(&hi2c2, NULL, 0, true);

  //printf("I2C4\r\n");
  //I2C_scan(&hi2c4, NULL, 0, true);
  TCA9548A_SelectChannel(0, 0); // seed config i2c
  I2C_scan(&hi2c1, NULL, 0, true);
  watchdog_refresh();
#endif

  // setup PDU monitor
  if((ADS7828_Init(&adc_mon[0], &hi2c2, 0x00) != HAL_OK) & (ADS7828_SetPowerMode(&adc_mon[0], ADS7828_PD_ON_REF_ON) != HAL_OK))
  {
	  printf("Failed to initialize ADC0\r\n");
  }else{
	  uint16_t raw;
	  ADS7828_ReadChannel(&adc_mon[0], 0, &raw);
  }

  if((ADS7828_Init(&adc_mon[1], &hi2c2, 0x03) != HAL_OK) & (ADS7828_SetPowerMode(&adc_mon[1], ADS7828_PD_ON_REF_ON) != HAL_OK))
  {
	  printf("Failed to initialize ADC0\r\n");
  }else{
	  uint16_t raw;
	  ADS7828_ReadChannel(&adc_mon[1], 0, &raw);
  }

  ADS7924_Init(&tec_ads, &hi2c2, 1, 3, ADS7924_ADDR_A0_DVDD, 3.300f, true);

  FAN_Init(&fan, &hi2c4, 0x2C);

  uint8_t fan_dev_id = FAN_ReadDeviceID(&fan);
  uint8_t fan_mfg_id = FAN_ReadManufacturerID(&fan);
  if(fan_dev_id != MAX6663_DEVICE_ID && fan_mfg_id != MAX6663_MAN_ID) {
	  printf("Failed to initialize Fan IC\r\n");
  } else {
	  printf("MAX6663 Device ID: 0x%02X, Manufacturer ID: 0x%02X\r\n", fan_dev_id, fan_mfg_id);

	  if(!FAN_EnableMonitoring(&fan)){
		  printf("Failed to enable fan monitoring\r\n");
	  }

	  FAN_SetManualPWM(&fan, 10);
  }

  // select GPIO expander channel
  TCA9548A_SelectChannel(1, 0);
  PCA9535APW_Init(&hi2c2);
  PCA9535APW_WritePin(0, 7, 1); // shut led off

  /* Boot-time I2C health scan: passively verify every expected device across
   * both muxes and the fan bus. Caches a snapshot the host reads via
   * OW_CTRL_I2C_STATUS. Runs before telemetry/USB so the bus is quiet. */
  console_i2c_health_scan();
  watchdog_refresh();

  // Init USB
  MX_USB_DEVICE_Init();
  watchdog_refresh();
  // Arm the EFT/EMC watchdog that recovers the OTG_FS link if it hangs.
  usb_recovery_init();
  // Initialize message queue for system JSON messages
  printf("Initialize message queue\r\n");
  mq_init();

  // Load motion config and apply settings
  motion_cfg_get();
  motion_cfg_apply_settings();
  watchdog_refresh();

  // Initialize odometers
  printf("Initialize odometers\r\n");
  if(Odometer_Init() != HAL_OK){
      printf("Failed to initialize odometers\r\n");
  }

  if (Serial_Init() != HAL_OK) {
      printf("Serial_Init failed — console serial number unavailable\r\n");
  }

  delay_ms_wdg(100);

  // Enable USB HUB
  HAL_GPIO_WritePin(HUB_RESET_GPIO_Port, HUB_RESET_Pin, GPIO_PIN_SET);
  delay_ms_wdg(100);

  comms_init();
  pdc_poll_init();

  /* FPGA configuration attestation: runs in the background from the main
   * loop; the trigger cannot be armed until it passes (fpga_attest.h). */
  fpga_attest_init(&s_xo2_handle);
  (void)fpga_attest_start();
  /* Start TIM4 interrupt for telemetry polling (250 ms) */
  HAL_TIM_Base_Start_IT(&htim4);

  /* Initialisation complete: tell the bootloader this image booted successfully
   * so its failsafe boot-counter resets. From here the main loop keeps the IWDG
   * (armed by the bootloader, re-initialised above) refreshed. */
  clear_boot_counter();

  /* USER CODE END 2 */

  /* Infinite loop */
  while (1)
  {

    /* USER CODE BEGIN 3 */
    Trigger_Service();  /* host-loss finish work deferred from the USB ISR (CFW-11) */
    comms_process();
    fpga_attest_service(FPGA_ATTEST_BUDGET_MS);
    if (fpga_attest_take_reapply_request()) {
      /* A completed run (re)established the per-unit limits: reload. */
      motion_cfg_apply_settings();
    }
    logging_pump();   /* flush USB-printf log data after command responses */
    telemetry_poll();
    usb_recovery_task();
    pdc_poll_tick();
    Odometer_Update_System();

    if (HAL_IWDG_Refresh(&hiwdg1) != HAL_OK)
    {
      /* Refresh Error */
      Error_Handler();
    }

    HAL_Delay(1);
  }
  /* USER CODE END 3 */
}

void SystemClock_Config(void)
{
  RCC_OscInitTypeDef RCC_OscInitStruct = {0};
  RCC_ClkInitTypeDef RCC_ClkInitStruct = {0};

  /** Supply configuration update enable
  */
  HAL_PWREx_ConfigSupply(PWR_LDO_SUPPLY);

  /** Configure the main internal regulator output voltage
  */
  __HAL_PWR_VOLTAGESCALING_CONFIG(PWR_REGULATOR_VOLTAGE_SCALE2);

  while(!__HAL_PWR_GET_FLAG(PWR_FLAG_VOSRDY)) {}

  /** Initializes the RCC Oscillators according to the specified parameters
  * in the RCC_OscInitTypeDef structure.
  */
  RCC_OscInitStruct.OscillatorType = RCC_OSCILLATORTYPE_HSI48|RCC_OSCILLATORTYPE_LSI
                              |RCC_OSCILLATORTYPE_HSE;
  RCC_OscInitStruct.HSEState = RCC_HSE_ON;
  RCC_OscInitStruct.LSIState = RCC_LSI_ON;
  RCC_OscInitStruct.HSI48State = RCC_HSI48_ON;
  RCC_OscInitStruct.PLL.PLLState = RCC_PLL_ON;
  RCC_OscInitStruct.PLL.PLLSource = RCC_PLLSOURCE_HSE;
  RCC_OscInitStruct.PLL.PLLM = 3;
  RCC_OscInitStruct.PLL.PLLN = 120;
  RCC_OscInitStruct.PLL.PLLP = 4;
  RCC_OscInitStruct.PLL.PLLQ = 16;
  RCC_OscInitStruct.PLL.PLLR = 16;
  RCC_OscInitStruct.PLL.PLLRGE = RCC_PLL1VCIRANGE_3;
  RCC_OscInitStruct.PLL.PLLVCOSEL = RCC_PLL1VCOWIDE;
  RCC_OscInitStruct.PLL.PLLFRACN = 0;
  if (HAL_RCC_OscConfig(&RCC_OscInitStruct) != HAL_OK)
  {
    Error_Handler();
  }

  /** Initializes the CPU, AHB and APB buses clocks
  */
  RCC_ClkInitStruct.ClockType = RCC_CLOCKTYPE_HCLK|RCC_CLOCKTYPE_SYSCLK
                              |RCC_CLOCKTYPE_PCLK1|RCC_CLOCKTYPE_PCLK2
                              |RCC_CLOCKTYPE_D3PCLK1|RCC_CLOCKTYPE_D1PCLK1;
  RCC_ClkInitStruct.SYSCLKSource = RCC_SYSCLKSOURCE_PLLCLK;
  RCC_ClkInitStruct.SYSCLKDivider = RCC_SYSCLK_DIV1;
  RCC_ClkInitStruct.AHBCLKDivider = RCC_HCLK_DIV2;
  RCC_ClkInitStruct.APB3CLKDivider = RCC_APB3_DIV1;
  RCC_ClkInitStruct.APB1CLKDivider = RCC_APB1_DIV1;
  RCC_ClkInitStruct.APB2CLKDivider = RCC_APB2_DIV1;
  RCC_ClkInitStruct.APB4CLKDivider = RCC_APB4_DIV1;

  if (HAL_RCC_ClockConfig(&RCC_ClkInitStruct, FLASH_LATENCY_2) != HAL_OK)
  {
    Error_Handler();
  }
}

void PeriphCommonClock_Config(void)
{
  RCC_PeriphCLKInitTypeDef PeriphClkInitStruct = {0};

  /** Initializes the peripherals clock
  */
  PeriphClkInitStruct.PeriphClockSelection = RCC_PERIPHCLK_I2C4|RCC_PERIPHCLK_I2C2
                              |RCC_PERIPHCLK_I2C1|RCC_PERIPHCLK_SPI4
                              |RCC_PERIPHCLK_UART4;
  PeriphClkInitStruct.PLL2.PLL2M = 3;
  PeriphClkInitStruct.PLL2.PLL2N = 120;
  PeriphClkInitStruct.PLL2.PLL2P = 2;
  PeriphClkInitStruct.PLL2.PLL2Q = 16;
  PeriphClkInitStruct.PLL2.PLL2R = 2;
  PeriphClkInitStruct.PLL2.PLL2RGE = RCC_PLL2VCIRANGE_3;
  PeriphClkInitStruct.PLL2.PLL2VCOSEL = RCC_PLL2VCOWIDE;
  PeriphClkInitStruct.PLL2.PLL2FRACN = 0;
  PeriphClkInitStruct.PLL3.PLL3M = 3;
  PeriphClkInitStruct.PLL3.PLL3N = 120;
  PeriphClkInitStruct.PLL3.PLL3P = 2;
  PeriphClkInitStruct.PLL3.PLL3Q = 16;
  PeriphClkInitStruct.PLL3.PLL3R = 16;
  PeriphClkInitStruct.PLL3.PLL3RGE = RCC_PLL3VCIRANGE_3;
  PeriphClkInitStruct.PLL3.PLL3VCOSEL = RCC_PLL3VCOWIDE;
  PeriphClkInitStruct.PLL3.PLL3FRACN = 0;
  PeriphClkInitStruct.Spi45ClockSelection = RCC_SPI45CLKSOURCE_PLL2;
  PeriphClkInitStruct.Usart234578ClockSelection = RCC_USART234578CLKSOURCE_PLL2;
  PeriphClkInitStruct.I2c123ClockSelection = RCC_I2C123CLKSOURCE_PLL3;
  PeriphClkInitStruct.I2c4ClockSelection = RCC_I2C4CLKSOURCE_PLL3;
  if (HAL_RCCEx_PeriphCLKConfig(&PeriphClkInitStruct) != HAL_OK)
  {
    Error_Handler();
  }
}

static void MX_CRC_Init(void)
{

  hcrc.Instance = CRC;
  hcrc.Init.DefaultPolynomialUse = DEFAULT_POLYNOMIAL_ENABLE;
  hcrc.Init.DefaultInitValueUse = DEFAULT_INIT_VALUE_ENABLE;
  hcrc.Init.InputDataInversionMode = CRC_INPUTDATA_INVERSION_NONE;
  hcrc.Init.OutputDataInversionMode = CRC_OUTPUTDATA_INVERSION_DISABLE;
  hcrc.InputDataFormat = CRC_INPUTDATA_FORMAT_BYTES;
  if (HAL_CRC_Init(&hcrc) != HAL_OK)
  {
    Error_Handler();
  }

}

static void MX_I2C1_Init(void)
{

  hi2c1.Instance = I2C1;
  /* 400 kHz fast mode (was 0x107075B0, 100 kHz). I2C1 carries only the mux 0
   * TCA9548A and the MachXO2 configuration ports (seed, TA, EE, OPT), all
   * rated for 400 kHz. Kernel clock 60 MHz (PLL3R): PRESC 1, SCLDEL 11,
   * SDADEL 7, SCLH 27, SCLL 39 -> tLOW 1.33 us, tHIGH 0.93 us, SCL 353-387 kHz
   * for 50-300 ns rise time; checked against the I2C fast-mode limits.
   * I2C2 and I2C4 stay at 100 kHz (they also carry the application FPGAs'
   * fabric I2C slaves, not qualified at 400 kHz). Shortens the configuration
   * attestation readback (fpga_attest.c). */
  hi2c1.Init.Timing = 0x10B71B27;
  hi2c1.Init.OwnAddress1 = 0;
  hi2c1.Init.AddressingMode = I2C_ADDRESSINGMODE_7BIT;
  hi2c1.Init.DualAddressMode = I2C_DUALADDRESS_DISABLE;
  hi2c1.Init.OwnAddress2 = 0;
  hi2c1.Init.OwnAddress2Masks = I2C_OA2_NOMASK;
  hi2c1.Init.GeneralCallMode = I2C_GENERALCALL_DISABLE;
  hi2c1.Init.NoStretchMode = I2C_NOSTRETCH_DISABLE;
  if (HAL_I2C_Init(&hi2c1) != HAL_OK)
  {
    Error_Handler();
  }

  /** Configure Analogue filter
  */
  if (HAL_I2CEx_ConfigAnalogFilter(&hi2c1, I2C_ANALOGFILTER_ENABLE) != HAL_OK)
  {
    Error_Handler();
  }

  /** Configure Digital filter
  */
  if (HAL_I2CEx_ConfigDigitalFilter(&hi2c1, 0) != HAL_OK)
  {
    Error_Handler();
  }

}

static void MX_I2C2_Init(void)
{

  hi2c2.Instance = I2C2;
  hi2c2.Init.Timing = 0x107075B0;
  hi2c2.Init.OwnAddress1 = 0;
  hi2c2.Init.AddressingMode = I2C_ADDRESSINGMODE_7BIT;
  hi2c2.Init.DualAddressMode = I2C_DUALADDRESS_DISABLE;
  hi2c2.Init.OwnAddress2 = 0;
  hi2c2.Init.OwnAddress2Masks = I2C_OA2_NOMASK;
  hi2c2.Init.GeneralCallMode = I2C_GENERALCALL_DISABLE;
  hi2c2.Init.NoStretchMode = I2C_NOSTRETCH_DISABLE;
  if (HAL_I2C_Init(&hi2c2) != HAL_OK)
  {
    Error_Handler();
  }

  /** Configure Analogue filter
  */
  if (HAL_I2CEx_ConfigAnalogFilter(&hi2c2, I2C_ANALOGFILTER_ENABLE) != HAL_OK)
  {
    Error_Handler();
  }

  /** Configure Digital filter
  */
  if (HAL_I2CEx_ConfigDigitalFilter(&hi2c2, 0) != HAL_OK)
  {
    Error_Handler();
  }

}

static void MX_I2C4_Init(void)
{

  hi2c4.Instance = I2C4;
  hi2c4.Init.Timing = 0x107075B0;
  hi2c4.Init.OwnAddress1 = 0;
  hi2c4.Init.AddressingMode = I2C_ADDRESSINGMODE_7BIT;
  hi2c4.Init.DualAddressMode = I2C_DUALADDRESS_DISABLE;
  hi2c4.Init.OwnAddress2 = 0;
  hi2c4.Init.OwnAddress2Masks = I2C_OA2_NOMASK;
  hi2c4.Init.GeneralCallMode = I2C_GENERALCALL_DISABLE;
  hi2c4.Init.NoStretchMode = I2C_NOSTRETCH_DISABLE;
  if (HAL_I2C_Init(&hi2c4) != HAL_OK)
  {
    Error_Handler();
  }

  /** Configure Analogue filter
  */
  if (HAL_I2CEx_ConfigAnalogFilter(&hi2c4, I2C_ANALOGFILTER_ENABLE) != HAL_OK)
  {
    Error_Handler();
  }

  /** Configure Digital filter
  */
  if (HAL_I2CEx_ConfigDigitalFilter(&hi2c4, 0) != HAL_OK)
  {
    Error_Handler();
  }

}

static void MX_IWDG1_Init(void)
{

  /* Timeout = (Reload + 1) * Prescaler / LSI = 1000 * 8 / 32000 = 250 ms:
   * 10 frame periods at 40 Hz (CFW-01, ARCH-82). After a fatal fault
   * Error_Handler() stops the trigger and stops refreshing, so the MCU resets
   * within this window. Window = 4095 leaves the early-refresh window off.
   * Everything that blocks longer than the window refreshes it while it
   * waits: the boot delays and scans (watchdog_refresh(), delay_ms_wdg()),
   * the user-config flash erase (Flash_Erase) and the XO2 FPGA programming
   * waits (pfmSecDelay = delay_ms_wdg). Measured on the bench: boot reaches
   * the main loop about 500 ms after HAL_Init, and the longest main-loop
   * iteration outside those waits is under 20 ms. The FPGAs are
   * factory-programmed and are no longer loaded at boot. */
  hiwdg1.Instance = IWDG1;
  hiwdg1.Init.Prescaler = IWDG_PRESCALER_8;
  hiwdg1.Init.Window = 4095;
  hiwdg1.Init.Reload = 999;
  if (HAL_IWDG_Init(&hiwdg1) != HAL_OK)
  {
    Error_Handler();
  }

}

static void MX_RNG_Init(void)
{

  hrng.Instance = RNG;
  hrng.Init.ClockErrorDetection = RNG_CED_ENABLE;
  if (HAL_RNG_Init(&hrng) != HAL_OK)
  {
    Error_Handler();
  }

}

static void MX_SPI1_Init(void)
{

  /* SPI1 parameter configuration*/
  hspi1.Instance = SPI1;
  hspi1.Init.Mode = SPI_MODE_MASTER;
  hspi1.Init.Direction = SPI_DIRECTION_2LINES;
  hspi1.Init.DataSize = SPI_DATASIZE_8BIT;
  hspi1.Init.CLKPolarity = SPI_POLARITY_LOW;
  hspi1.Init.CLKPhase = SPI_PHASE_2EDGE;
  hspi1.Init.NSS = SPI_NSS_SOFT;
  hspi1.Init.BaudRatePrescaler = SPI_BAUDRATEPRESCALER_64;
  hspi1.Init.FirstBit = SPI_FIRSTBIT_MSB;
  hspi1.Init.TIMode = SPI_TIMODE_DISABLE;
  hspi1.Init.CRCCalculation = SPI_CRCCALCULATION_DISABLE;
  hspi1.Init.CRCPolynomial = 0x0;
  hspi1.Init.NSSPMode = SPI_NSS_PULSE_DISABLE;
  hspi1.Init.NSSPolarity = SPI_NSS_POLARITY_LOW;
  hspi1.Init.FifoThreshold = SPI_FIFO_THRESHOLD_01DATA;
  hspi1.Init.TxCRCInitializationPattern = SPI_CRC_INITIALIZATION_ALL_ZERO_PATTERN;
  hspi1.Init.RxCRCInitializationPattern = SPI_CRC_INITIALIZATION_ALL_ZERO_PATTERN;
  hspi1.Init.MasterSSIdleness = SPI_MASTER_SS_IDLENESS_00CYCLE;
  hspi1.Init.MasterInterDataIdleness = SPI_MASTER_INTERDATA_IDLENESS_00CYCLE;
  hspi1.Init.MasterReceiverAutoSusp = SPI_MASTER_RX_AUTOSUSP_DISABLE;
  hspi1.Init.MasterKeepIOState = SPI_MASTER_KEEP_IO_STATE_DISABLE;
  hspi1.Init.IOSwap = SPI_IO_SWAP_DISABLE;
  if (HAL_SPI_Init(&hspi1) != HAL_OK)
  {
    Error_Handler();
  }

}

static void MX_SPI2_Init(void)
{

  /* SPI2 parameter configuration*/
  hspi2.Instance = SPI2;
  hspi2.Init.Mode = SPI_MODE_MASTER;
  hspi2.Init.Direction = SPI_DIRECTION_2LINES;
  hspi2.Init.DataSize = SPI_DATASIZE_4BIT;
  hspi2.Init.CLKPolarity = SPI_POLARITY_LOW;
  hspi2.Init.CLKPhase = SPI_PHASE_1EDGE;
  hspi2.Init.NSS = SPI_NSS_SOFT;
  hspi2.Init.BaudRatePrescaler = SPI_BAUDRATEPRESCALER_2;
  hspi2.Init.FirstBit = SPI_FIRSTBIT_MSB;
  hspi2.Init.TIMode = SPI_TIMODE_DISABLE;
  hspi2.Init.CRCCalculation = SPI_CRCCALCULATION_DISABLE;
  hspi2.Init.CRCPolynomial = 0x0;
  hspi2.Init.NSSPMode = SPI_NSS_PULSE_ENABLE;
  hspi2.Init.NSSPolarity = SPI_NSS_POLARITY_LOW;
  hspi2.Init.FifoThreshold = SPI_FIFO_THRESHOLD_01DATA;
  hspi2.Init.TxCRCInitializationPattern = SPI_CRC_INITIALIZATION_ALL_ZERO_PATTERN;
  hspi2.Init.RxCRCInitializationPattern = SPI_CRC_INITIALIZATION_ALL_ZERO_PATTERN;
  hspi2.Init.MasterSSIdleness = SPI_MASTER_SS_IDLENESS_00CYCLE;
  hspi2.Init.MasterInterDataIdleness = SPI_MASTER_INTERDATA_IDLENESS_00CYCLE;
  hspi2.Init.MasterReceiverAutoSusp = SPI_MASTER_RX_AUTOSUSP_DISABLE;
  hspi2.Init.MasterKeepIOState = SPI_MASTER_KEEP_IO_STATE_DISABLE;
  hspi2.Init.IOSwap = SPI_IO_SWAP_DISABLE;
  if (HAL_SPI_Init(&hspi2) != HAL_OK)
  {
    Error_Handler();
  }

}

static void MX_SPI3_Init(void)
{

  /* SPI3 parameter configuration*/
  hspi3.Instance = SPI3;
  hspi3.Init.Mode = SPI_MODE_MASTER;
  hspi3.Init.Direction = SPI_DIRECTION_2LINES;
  hspi3.Init.DataSize = SPI_DATASIZE_4BIT;
  hspi3.Init.CLKPolarity = SPI_POLARITY_LOW;
  hspi3.Init.CLKPhase = SPI_PHASE_1EDGE;
  hspi3.Init.NSS = SPI_NSS_SOFT;
  hspi3.Init.BaudRatePrescaler = SPI_BAUDRATEPRESCALER_2;
  hspi3.Init.FirstBit = SPI_FIRSTBIT_MSB;
  hspi3.Init.TIMode = SPI_TIMODE_DISABLE;
  hspi3.Init.CRCCalculation = SPI_CRCCALCULATION_DISABLE;
  hspi3.Init.CRCPolynomial = 0x0;
  hspi3.Init.NSSPMode = SPI_NSS_PULSE_ENABLE;
  hspi3.Init.NSSPolarity = SPI_NSS_POLARITY_LOW;
  hspi3.Init.FifoThreshold = SPI_FIFO_THRESHOLD_01DATA;
  hspi3.Init.TxCRCInitializationPattern = SPI_CRC_INITIALIZATION_ALL_ZERO_PATTERN;
  hspi3.Init.RxCRCInitializationPattern = SPI_CRC_INITIALIZATION_ALL_ZERO_PATTERN;
  hspi3.Init.MasterSSIdleness = SPI_MASTER_SS_IDLENESS_00CYCLE;
  hspi3.Init.MasterInterDataIdleness = SPI_MASTER_INTERDATA_IDLENESS_00CYCLE;
  hspi3.Init.MasterReceiverAutoSusp = SPI_MASTER_RX_AUTOSUSP_DISABLE;
  hspi3.Init.MasterKeepIOState = SPI_MASTER_KEEP_IO_STATE_DISABLE;
  hspi3.Init.IOSwap = SPI_IO_SWAP_DISABLE;
  if (HAL_SPI_Init(&hspi3) != HAL_OK)
  {
    Error_Handler();
  }

}

static void MX_SPI4_Init(void)
{

  /* SPI4 parameter configuration*/
  hspi4.Instance = SPI4;
  hspi4.Init.Mode = SPI_MODE_MASTER;
  hspi4.Init.Direction = SPI_DIRECTION_2LINES;
  hspi4.Init.DataSize = SPI_DATASIZE_4BIT;
  hspi4.Init.CLKPolarity = SPI_POLARITY_LOW;
  hspi4.Init.CLKPhase = SPI_PHASE_1EDGE;
  hspi4.Init.NSS = SPI_NSS_SOFT;
  hspi4.Init.BaudRatePrescaler = SPI_BAUDRATEPRESCALER_2;
  hspi4.Init.FirstBit = SPI_FIRSTBIT_MSB;
  hspi4.Init.TIMode = SPI_TIMODE_DISABLE;
  hspi4.Init.CRCCalculation = SPI_CRCCALCULATION_DISABLE;
  hspi4.Init.CRCPolynomial = 0x0;
  hspi4.Init.NSSPMode = SPI_NSS_PULSE_ENABLE;
  hspi4.Init.NSSPolarity = SPI_NSS_POLARITY_LOW;
  hspi4.Init.FifoThreshold = SPI_FIFO_THRESHOLD_01DATA;
  hspi4.Init.TxCRCInitializationPattern = SPI_CRC_INITIALIZATION_ALL_ZERO_PATTERN;
  hspi4.Init.RxCRCInitializationPattern = SPI_CRC_INITIALIZATION_ALL_ZERO_PATTERN;
  hspi4.Init.MasterSSIdleness = SPI_MASTER_SS_IDLENESS_00CYCLE;
  hspi4.Init.MasterInterDataIdleness = SPI_MASTER_INTERDATA_IDLENESS_00CYCLE;
  hspi4.Init.MasterReceiverAutoSusp = SPI_MASTER_RX_AUTOSUSP_DISABLE;
  hspi4.Init.MasterKeepIOState = SPI_MASTER_KEEP_IO_STATE_DISABLE;
  hspi4.Init.IOSwap = SPI_IO_SWAP_DISABLE;
  if (HAL_SPI_Init(&hspi4) != HAL_OK)
  {
    Error_Handler();
  }

}

static void MX_TIM1_Init(void)
{

  TIM_ClockConfigTypeDef sClockSourceConfig = {0};
  TIM_MasterConfigTypeDef sMasterConfig = {0};

  htim1.Instance = TIM1;
  htim1.Init.Prescaler = 0;
  htim1.Init.CounterMode = TIM_COUNTERMODE_UP;
  htim1.Init.Period = 65535;
  htim1.Init.ClockDivision = TIM_CLOCKDIVISION_DIV1;
  htim1.Init.RepetitionCounter = 0;
  htim1.Init.AutoReloadPreload = TIM_AUTORELOAD_PRELOAD_DISABLE;
  if (HAL_TIM_Base_Init(&htim1) != HAL_OK)
  {
    Error_Handler();
  }
  sClockSourceConfig.ClockSource = TIM_CLOCKSOURCE_INTERNAL;
  if (HAL_TIM_ConfigClockSource(&htim1, &sClockSourceConfig) != HAL_OK)
  {
    Error_Handler();
  }
  sMasterConfig.MasterOutputTrigger = TIM_TRGO_RESET;
  sMasterConfig.MasterOutputTrigger2 = TIM_TRGO2_RESET;
  sMasterConfig.MasterSlaveMode = TIM_MASTERSLAVEMODE_DISABLE;
  if (HAL_TIMEx_MasterConfigSynchronization(&htim1, &sMasterConfig) != HAL_OK)
  {
    Error_Handler();
  }

}

static void MX_TIM2_Init(void)
{

  TIM_ClockConfigTypeDef sClockSourceConfig = {0};
  TIM_MasterConfigTypeDef sMasterConfig = {0};
  TIM_OC_InitTypeDef sConfigOC = {0};

  htim2.Instance = TIM2;
  htim2.Init.Prescaler = 120-1;
  htim2.Init.CounterMode = TIM_COUNTERMODE_UP;
  htim2.Init.Period = 25000-1;
  htim2.Init.ClockDivision = TIM_CLOCKDIVISION_DIV1;
  htim2.Init.AutoReloadPreload = TIM_AUTORELOAD_PRELOAD_DISABLE;
  if (HAL_TIM_Base_Init(&htim2) != HAL_OK)
  {
    Error_Handler();
  }
  sClockSourceConfig.ClockSource = TIM_CLOCKSOURCE_INTERNAL;
  if (HAL_TIM_ConfigClockSource(&htim2, &sClockSourceConfig) != HAL_OK)
  {
    Error_Handler();
  }
  if (HAL_TIM_PWM_Init(&htim2) != HAL_OK)
  {
    Error_Handler();
  }
  sMasterConfig.MasterOutputTrigger = TIM_TRGO_UPDATE;
  sMasterConfig.MasterSlaveMode = TIM_MASTERSLAVEMODE_DISABLE;
  if (HAL_TIMEx_MasterConfigSynchronization(&htim2, &sMasterConfig) != HAL_OK)
  {
    Error_Handler();
  }
  sConfigOC.OCMode = TIM_OCMODE_PWM1;
  sConfigOC.Pulse = 1000;
  sConfigOC.OCPolarity = TIM_OCPOLARITY_HIGH;
  sConfigOC.OCFastMode = TIM_OCFAST_DISABLE;
  if (HAL_TIM_PWM_ConfigChannel(&htim2, &sConfigOC, TIM_CHANNEL_1) != HAL_OK)
  {
    Error_Handler();
  }
  HAL_TIM_MspPostInit(&htim2);

}

static void MX_TIM3_Init(void)
{

  TIM_ClockConfigTypeDef sClockSourceConfig = {0};
  TIM_SlaveConfigTypeDef sSlaveConfig = {0};
  TIM_MasterConfigTypeDef sMasterConfig = {0};
  TIM_OC_InitTypeDef sConfigOC = {0};

  htim3.Instance = TIM3;
  htim3.Init.Prescaler = 120-1;
  htim3.Init.CounterMode = TIM_COUNTERMODE_UP;
  htim3.Init.Period = 1250-1;
  htim3.Init.ClockDivision = TIM_CLOCKDIVISION_DIV1;
  htim3.Init.AutoReloadPreload = TIM_AUTORELOAD_PRELOAD_DISABLE;
  if (HAL_TIM_Base_Init(&htim3) != HAL_OK)
  {
    Error_Handler();
  }
  sClockSourceConfig.ClockSource = TIM_CLOCKSOURCE_INTERNAL;
  if (HAL_TIM_ConfigClockSource(&htim3, &sClockSourceConfig) != HAL_OK)
  {
    Error_Handler();
  }
  if (HAL_TIM_PWM_Init(&htim3) != HAL_OK)
  {
    Error_Handler();
  }
  if (HAL_TIM_OnePulse_Init(&htim3, TIM_OPMODE_SINGLE) != HAL_OK)
  {
    Error_Handler();
  }
  sSlaveConfig.SlaveMode = TIM_SLAVEMODE_TRIGGER;
  sSlaveConfig.InputTrigger = TIM_TS_ITR1;
  if (HAL_TIM_SlaveConfigSynchro(&htim3, &sSlaveConfig) != HAL_OK)
  {
    Error_Handler();
  }
  sMasterConfig.MasterOutputTrigger = TIM_TRGO_RESET;
  sMasterConfig.MasterSlaveMode = TIM_MASTERSLAVEMODE_DISABLE;
  if (HAL_TIMEx_MasterConfigSynchronization(&htim3, &sMasterConfig) != HAL_OK)
  {
    Error_Handler();
  }
  sConfigOC.OCMode = TIM_OCMODE_PWM1;
  sConfigOC.Pulse = 250;
  sConfigOC.OCPolarity = TIM_OCPOLARITY_LOW;
  sConfigOC.OCFastMode = TIM_OCFAST_DISABLE;
  if (HAL_TIM_PWM_ConfigChannel(&htim3, &sConfigOC, TIM_CHANNEL_1) != HAL_OK)
  {
    Error_Handler();
  }
  /* USER CODE BEGIN TIM3_Init 2 */

  __HAL_TIM_ENABLE_OCxPRELOAD(&htim3, TIM_CHANNEL_1); // Enable preload for CCR1 (important for correct PWM timing in OPM)
  htim3.Instance->CCER |= TIM_CCER_CC1E; // Enable CH1 output
  __HAL_TIM_ENABLE(&htim3); // Allow TIM3 to respond to triggers

  /* USER CODE END TIM3_Init 2 */
  HAL_TIM_MspPostInit(&htim3);

}

static void MX_TIM4_Init(void)
{

  TIM_ClockConfigTypeDef sClockSourceConfig = {0};
  TIM_MasterConfigTypeDef sMasterConfig = {0};

  htim4.Instance = TIM4;
  htim4.Init.Prescaler = 12000-1;
  htim4.Init.CounterMode = TIM_COUNTERMODE_UP;
  htim4.Init.Period = 2500-1;
  htim4.Init.ClockDivision = TIM_CLOCKDIVISION_DIV1;
  htim4.Init.AutoReloadPreload = TIM_AUTORELOAD_PRELOAD_DISABLE;
  if (HAL_TIM_Base_Init(&htim4) != HAL_OK)
  {
    Error_Handler();
  }
  sClockSourceConfig.ClockSource = TIM_CLOCKSOURCE_INTERNAL;
  if (HAL_TIM_ConfigClockSource(&htim4, &sClockSourceConfig) != HAL_OK)
  {
    Error_Handler();
  }
  sMasterConfig.MasterOutputTrigger = TIM_TRGO_RESET;
  sMasterConfig.MasterSlaveMode = TIM_MASTERSLAVEMODE_DISABLE;
  if (HAL_TIMEx_MasterConfigSynchronization(&htim4, &sMasterConfig) != HAL_OK)
  {
    Error_Handler();
  }

}

static void MX_TIM8_Init(void)
{

  TIM_ClockConfigTypeDef sClockSourceConfig = {0};
  TIM_MasterConfigTypeDef sMasterConfig = {0};

  htim8.Instance = TIM8;
  htim8.Init.Prescaler = 12000-1;
  htim8.Init.CounterMode = TIM_COUNTERMODE_UP;
  htim8.Init.Period = 2500-1;
  htim8.Init.ClockDivision = TIM_CLOCKDIVISION_DIV1;
  htim8.Init.RepetitionCounter = 0;
  htim8.Init.AutoReloadPreload = TIM_AUTORELOAD_PRELOAD_DISABLE;
  if (HAL_TIM_Base_Init(&htim8) != HAL_OK)
  {
    Error_Handler();
  }
  sClockSourceConfig.ClockSource = TIM_CLOCKSOURCE_INTERNAL;
  if (HAL_TIM_ConfigClockSource(&htim8, &sClockSourceConfig) != HAL_OK)
  {
    Error_Handler();
  }
  sMasterConfig.MasterOutputTrigger = TIM_TRGO_RESET;
  sMasterConfig.MasterOutputTrigger2 = TIM_TRGO2_RESET;
  sMasterConfig.MasterSlaveMode = TIM_MASTERSLAVEMODE_DISABLE;
  if (HAL_TIMEx_MasterConfigSynchronization(&htim8, &sMasterConfig) != HAL_OK)
  {
    Error_Handler();
  }

}

static void MX_TIM12_Init(void)
{

  TIM_ClockConfigTypeDef sClockSourceConfig = {0};
  TIM_MasterConfigTypeDef sMasterConfig = {0};

  htim12.Instance = TIM12;
  htim12.Init.Prescaler = 120-1;
  htim12.Init.CounterMode = TIM_COUNTERMODE_UP;
  htim12.Init.Period = 25000-1;
  htim12.Init.ClockDivision = TIM_CLOCKDIVISION_DIV1;
  htim12.Init.AutoReloadPreload = TIM_AUTORELOAD_PRELOAD_DISABLE;
  if (HAL_TIM_Base_Init(&htim12) != HAL_OK)
  {
    Error_Handler();
  }
  sClockSourceConfig.ClockSource = TIM_CLOCKSOURCE_INTERNAL;
  if (HAL_TIM_ConfigClockSource(&htim12, &sClockSourceConfig) != HAL_OK)
  {
    Error_Handler();
  }
  sMasterConfig.MasterOutputTrigger = TIM_TRGO_RESET;
  sMasterConfig.MasterSlaveMode = TIM_MASTERSLAVEMODE_DISABLE;
  if (HAL_TIMEx_MasterConfigSynchronization(&htim12, &sMasterConfig) != HAL_OK)
  {
    Error_Handler();
  }

}

static void MX_TIM15_Init(void)
{

  TIM_ClockConfigTypeDef sClockSourceConfig = {0};
  TIM_MasterConfigTypeDef sMasterConfig = {0};

  htim15.Instance = TIM15;
  htim15.Init.Prescaler = 1200-1;
  htim15.Init.CounterMode = TIM_COUNTERMODE_UP;
  htim15.Init.Period = 8000-1;
  htim15.Init.ClockDivision = TIM_CLOCKDIVISION_DIV1;
  htim15.Init.RepetitionCounter = 0;
  htim15.Init.AutoReloadPreload = TIM_AUTORELOAD_PRELOAD_DISABLE;
  if (HAL_TIM_Base_Init(&htim15) != HAL_OK)
  {
    Error_Handler();
  }
  sClockSourceConfig.ClockSource = TIM_CLOCKSOURCE_INTERNAL;
  if (HAL_TIM_ConfigClockSource(&htim15, &sClockSourceConfig) != HAL_OK)
  {
    Error_Handler();
  }
  sMasterConfig.MasterOutputTrigger = TIM_TRGO_RESET;
  sMasterConfig.MasterSlaveMode = TIM_MASTERSLAVEMODE_DISABLE;
  if (HAL_TIMEx_MasterConfigSynchronization(&htim15, &sMasterConfig) != HAL_OK)
  {
    Error_Handler();
  }

}

static void MX_UART4_Init(void)
{

  huart4.Instance = UART4;
  huart4.Init.BaudRate = 115200;
  huart4.Init.WordLength = UART_WORDLENGTH_8B;
  huart4.Init.StopBits = UART_STOPBITS_1;
  huart4.Init.Parity = UART_PARITY_NONE;
  huart4.Init.Mode = UART_MODE_TX_RX;
  huart4.Init.HwFlowCtl = UART_HWCONTROL_NONE;
  huart4.Init.OverSampling = UART_OVERSAMPLING_16;
  huart4.Init.OneBitSampling = UART_ONE_BIT_SAMPLE_DISABLE;
  huart4.Init.ClockPrescaler = UART_PRESCALER_DIV1;
  huart4.AdvancedInit.AdvFeatureInit = UART_ADVFEATURE_NO_INIT;
  if (HAL_UART_Init(&huart4) != HAL_OK)
  {
    Error_Handler();
  }
  if (HAL_UARTEx_SetTxFifoThreshold(&huart4, UART_TXFIFO_THRESHOLD_1_8) != HAL_OK)
  {
    Error_Handler();
  }
  if (HAL_UARTEx_SetRxFifoThreshold(&huart4, UART_RXFIFO_THRESHOLD_1_8) != HAL_OK)
  {
    Error_Handler();
  }
  if (HAL_UARTEx_DisableFifoMode(&huart4) != HAL_OK)
  {
    Error_Handler();
  }

}

static void MX_DMA_Init(void)
{

  /* DMA controller clock enable */
  __HAL_RCC_DMA1_CLK_ENABLE();

  /* DMA interrupt init */
  /* DMA1_Stream0_IRQn interrupt configuration */
  HAL_NVIC_SetPriority(DMA1_Stream0_IRQn, 0, 0);
  HAL_NVIC_EnableIRQ(DMA1_Stream0_IRQn);
  /* DMA1_Stream1_IRQn interrupt configuration */
  HAL_NVIC_SetPriority(DMA1_Stream1_IRQn, 0, 0);
  HAL_NVIC_EnableIRQ(DMA1_Stream1_IRQn);

}

static void MX_GPIO_Init(void)
{
  GPIO_InitTypeDef GPIO_InitStruct = {0};

  /* GPIO Ports Clock Enable */
  __HAL_RCC_GPIOC_CLK_ENABLE();
  __HAL_RCC_GPIOE_CLK_ENABLE();
  __HAL_RCC_GPIOB_CLK_ENABLE();
  __HAL_RCC_GPIOA_CLK_ENABLE();
  __HAL_RCC_GPIOD_CLK_ENABLE();
  __HAL_RCC_GPIOH_CLK_ENABLE();

  /*Configure GPIO pin Output Level */
  HAL_GPIO_WritePin(GPIOC, HUB_RESET_Pin|SDA_REM_Pin, GPIO_PIN_RESET);

  /*Configure GPIO pin Output Level */
  HAL_GPIO_WritePin(GPIOE, nTRIG_Pin|TECDAC_SS_Pin|TA_CS_Pin, GPIO_PIN_SET);

  /*Configure GPIO pin Output Level */
  HAL_GPIO_WritePin(GPIOA, EE_CS_Pin|IO_EXP_RSTN_Pin|IND1_Pin|enSyncOUT_Pin, GPIO_PIN_SET);

  /*Configure GPIO pin Output Level */
  HAL_GPIO_WritePin(GPIOD, IND3_Pin|IND2_Pin, GPIO_PIN_SET);

  /*Configure GPIO pin Output Level */
  HAL_GPIO_WritePin(SCL_CFG_GPIO_Port, SCL_CFG_Pin, GPIO_PIN_RESET);

  /*Configure GPIO pin Output Level */
  HAL_GPIO_WritePin(GPIOB, SEED_CS_Pin|OPT_CS_Pin, GPIO_PIN_SET);

  /*Configure GPIO pin Output Level */
  HAL_GPIO_WritePin(enSyncIN_GPIO_Port, enSyncIN_Pin, GPIO_PIN_RESET);

  /*Configure GPIO pins : HUB_RESET_Pin SDA_REM_Pin */
  GPIO_InitStruct.Pin = HUB_RESET_Pin|SDA_REM_Pin;
  GPIO_InitStruct.Mode = GPIO_MODE_OUTPUT_PP;
  GPIO_InitStruct.Pull = GPIO_NOPULL;
  GPIO_InitStruct.Speed = GPIO_SPEED_FREQ_LOW;
  HAL_GPIO_Init(GPIOC, &GPIO_InitStruct);

  /*Configure GPIO pins : nTRIG_Pin TECDAC_SS_Pin TA_CS_Pin */
  GPIO_InitStruct.Pin = nTRIG_Pin|TECDAC_SS_Pin|TA_CS_Pin;
  GPIO_InitStruct.Mode = GPIO_MODE_OUTPUT_PP;
  GPIO_InitStruct.Pull = GPIO_NOPULL;
  GPIO_InitStruct.Speed = GPIO_SPEED_FREQ_LOW;
  HAL_GPIO_Init(GPIOE, &GPIO_InitStruct);

  /*Configure GPIO pin : SYS_EN_Pin */
  GPIO_InitStruct.Pin = SYS_EN_Pin;
  GPIO_InitStruct.Mode = GPIO_MODE_INPUT;
  GPIO_InitStruct.Pull = GPIO_NOPULL;
  HAL_GPIO_Init(SYS_EN_GPIO_Port, &GPIO_InitStruct);

  /*Configure GPIO pins : EE_CS_Pin SCL_CFG_Pin IO_EXP_RSTN_Pin IND1_Pin
                           enSyncOUT_Pin */
  GPIO_InitStruct.Pin = EE_CS_Pin|SCL_CFG_Pin|IO_EXP_RSTN_Pin|IND1_Pin
                          |enSyncOUT_Pin;
  GPIO_InitStruct.Mode = GPIO_MODE_OUTPUT_PP;
  GPIO_InitStruct.Pull = GPIO_NOPULL;
  GPIO_InitStruct.Speed = GPIO_SPEED_FREQ_LOW;
  HAL_GPIO_Init(GPIOA, &GPIO_InitStruct);

  /*Configure GPIO pins : IND3_Pin IND2_Pin enSyncIN_Pin */
  GPIO_InitStruct.Pin = IND3_Pin|IND2_Pin|enSyncIN_Pin;
  GPIO_InitStruct.Mode = GPIO_MODE_OUTPUT_PP;
  GPIO_InitStruct.Pull = GPIO_NOPULL;
  GPIO_InitStruct.Speed = GPIO_SPEED_FREQ_LOW;
  HAL_GPIO_Init(GPIOD, &GPIO_InitStruct);

  /*Configure GPIO pins : SP_GPIO2_Pin SYNC_OUT_Pin SYNC_IN_Pin FULL_ON_n_Pin
                           SP_GPIO1_Pin */
  GPIO_InitStruct.Pin = SP_GPIO2_Pin|SYNC_OUT_Pin|SYNC_IN_Pin|FULL_ON_n_Pin
                          |SP_GPIO1_Pin;
  GPIO_InitStruct.Mode = GPIO_MODE_INPUT;
  GPIO_InitStruct.Pull = GPIO_NOPULL;
  HAL_GPIO_Init(GPIOD, &GPIO_InitStruct);

  /*Configure GPIO pins : FAN_TOP_GD2_Pin MCU_GPIO1_Pin TEMPGD_Pin FAN_TOP_GD3_Pin
                           BRD_V2_Pin FAN_TOP_GD4_Pin BRD_V0_Pin */
  GPIO_InitStruct.Pin = FAN_TOP_GD2_Pin|MCU_GPIO1_Pin|TEMPGD_Pin|FAN_TOP_GD3_Pin
                          |BRD_V2_Pin|FAN_TOP_GD4_Pin|BRD_V0_Pin;
  GPIO_InitStruct.Mode = GPIO_MODE_INPUT;
  GPIO_InitStruct.Pull = GPIO_NOPULL;
  HAL_GPIO_Init(GPIOE, &GPIO_InitStruct);

  /*Configure GPIO pins : FAN_TOP_GD1_Pin SP_GPIO3_Pin */
  GPIO_InitStruct.Pin = FAN_TOP_GD1_Pin|SP_GPIO3_Pin;
  GPIO_InitStruct.Mode = GPIO_MODE_INPUT;
  GPIO_InitStruct.Pull = GPIO_NOPULL;
  HAL_GPIO_Init(GPIOC, &GPIO_InitStruct);

  /*Configure GPIO pins : EE_INT_Pin OPT_INT_Pin */
  GPIO_InitStruct.Pin = EE_INT_Pin|OPT_INT_Pin;
  GPIO_InitStruct.Mode = GPIO_MODE_IT_RISING;
  GPIO_InitStruct.Pull = GPIO_NOPULL;
  HAL_GPIO_Init(GPIOC, &GPIO_InitStruct);

  /*Configure GPIO pin : BRD_V1_Pin */
  GPIO_InitStruct.Pin = BRD_V1_Pin;
  GPIO_InitStruct.Mode = GPIO_MODE_IT_RISING;
  GPIO_InitStruct.Pull = GPIO_NOPULL;
  HAL_GPIO_Init(BRD_V1_GPIO_Port, &GPIO_InitStruct);

  /*Configure GPIO pins : SEED_CS_Pin OPT_CS_Pin */
  GPIO_InitStruct.Pin = SEED_CS_Pin|OPT_CS_Pin;
  GPIO_InitStruct.Mode = GPIO_MODE_OUTPUT_PP;
  GPIO_InitStruct.Pull = GPIO_NOPULL;
  GPIO_InitStruct.Speed = GPIO_SPEED_FREQ_LOW;
  HAL_GPIO_Init(GPIOB, &GPIO_InitStruct);

}

/* USER CODE BEGIN 4 */

void HAL_UARTEx_RxEventCallback(UART_HandleTypeDef *huart, uint16_t Size)
{
}

void HAL_UART_RxHalfCpltCallback(UART_HandleTypeDef *huart)
{
}

void HAL_UART_RxCpltCallback(UART_HandleTypeDef *huart)
{

}

void HAL_UART_TxCpltCallback(UART_HandleTypeDef *huart)
{
	if(huart->Instance == UART4)
	{
		logging_UART_TxCpltCallback(huart);
	}
}

void HAL_UART_ErrorCallback(UART_HandleTypeDef *huart) {

    if (huart->Instance == USART1) {
        // Handle errors here. Maybe reset DMA reception, etc.
        comms_handle_ErrorCallback(huart);
    }
}

void HAL_TIM_OC_DelayElapsedCallback(TIM_HandleTypeDef *htim)
{
	  if (htim->Instance == TIM2) {
		  FSYNC_DelayElapsedCallback(htim);
	  }

	  if (htim->Instance == TIM3) {
	  	  LSYNC_DelayElapsedCallback(htim);
	  }
}

void HAL_I2C_MasterTxCpltCallback(I2C_HandleTypeDef *hi2c)
{
  if (hi2c->Instance == I2C1)
  {
    MXO_I2C_MasterTxCpltCallback(hi2c);
  }
}

void HAL_I2C_MasterRxCpltCallback(I2C_HandleTypeDef *hi2c)
{
  if (hi2c->Instance == I2C1)
  {
    MXO_I2C_MasterRxCpltCallback(hi2c);
  }
}

void HAL_I2C_ErrorCallback(I2C_HandleTypeDef *hi2c)
{
  if (hi2c->Instance == I2C1)
  {
    MXO_I2C_ErrorCallback(hi2c);
  }
}

/* USER CODE END 4 */

 /* MPU Configuration */

void MPU_Config(void)
{
  MPU_Region_InitTypeDef MPU_InitStruct = {0};

  /* Disables the MPU */
  HAL_MPU_Disable();

  /** Initializes and configures the Region and the memory to be protected
  */
  MPU_InitStruct.Enable = MPU_REGION_ENABLE;
  MPU_InitStruct.Number = MPU_REGION_NUMBER0;
  MPU_InitStruct.BaseAddress = 0x0;
  MPU_InitStruct.Size = MPU_REGION_SIZE_4GB;
  MPU_InitStruct.SubRegionDisable = 0x87;
  MPU_InitStruct.TypeExtField = MPU_TEX_LEVEL0;
  MPU_InitStruct.AccessPermission = MPU_REGION_NO_ACCESS;
  MPU_InitStruct.DisableExec = MPU_INSTRUCTION_ACCESS_DISABLE;
  MPU_InitStruct.IsShareable = MPU_ACCESS_SHAREABLE;
  MPU_InitStruct.IsCacheable = MPU_ACCESS_NOT_CACHEABLE;
  MPU_InitStruct.IsBufferable = MPU_ACCESS_NOT_BUFFERABLE;

  HAL_MPU_ConfigRegion(&MPU_InitStruct);
  /* Enables the MPU */
  HAL_MPU_Enable(MPU_PRIVILEGED_DEFAULT);

}

void HAL_TIM_PeriodElapsedCallback(TIM_HandleTypeDef *htim)
{
  /* USER CODE BEGIN Callback 0 */
  if (htim->Instance == TIM4) {
    comms_telemetry_tick();
  }
  if (htim->Instance == FSYNC_TIMER.Instance) {
    FSYNC_PeriodElapsedCallback(htim);
  }
  if (htim->Instance == LASER_TIMER.Instance) {
    LSYNC_PeriodElapsedCallback(htim);
  }

  if (htim->Instance == TIM12) {
	  CDC_Idle_Timer_Handler();
  }

  /* USER CODE END Callback 0 */
  if (htim->Instance == TIM17)
  {
    HAL_IncTick();
  }
  /* USER CODE BEGIN Callback 1 */
  if (htim->Instance == TIM15) {
    HAL_TIM_Base_Stop_IT(htim);
    if(_enter_dfu) {
#if defined(BARE_METAL_BUILD)
      /* Bare-metal build: no custom bootloader. Arm the RAM magic that
       * CheckBootloaderFlag() (in system_stm32h7xx.c) reads first thing after
       * the reset below; it then jumps to the STM32 system-memory ROM DFU
       * loader. D3 SRAM survives the software reset. */
      *((volatile uint32_t *)0x38000000) = 0xDEADBEEFU; /* BL_DFU_RAM_FLAG_MAGIC */
      __DSB();
#else
      /* Request DFU from the custom secure bootloader (NOT the STM32 ROM
       * loader, which is disabled in production). The bootloader reads this
       * backup register on the next reset and, when it holds the magic, enters
       * its USB DFU instead of launching the application. The register lives in
       * the VBAT/backup domain and survives the software reset below.
       *
       * Direct CMSIS access (HAL RTC module is not enabled in this build):
       * unlock the backup domain (DBP), clock the RTC APB register interface
       * and kernel (LSI), then arm BL_FORCE_DFU_MAGIC in RTC->BKP7R. */
      PWR->CR1   |= PWR_CR1_DBP;            /* disable backup-domain write protect */
      RCC->APB4ENR |= RCC_APB4ENR_RTCAPBEN; /* RTC register APB interface clock     */
      RCC->CSR   |= RCC_CSR_LSION;          /* LSI on (RTC kernel clock source)     */
      { uint32_t to = 0U;
        while (((RCC->CSR & RCC_CSR_LSIRDY) == 0U) && (++to < 0x00100000U)) { } }
      if ((RCC->BDCR & RCC_BDCR_RTCSEL) == 0U) {
        RCC->BDCR = (RCC->BDCR & ~RCC_BDCR_RTCSEL) | RCC_BDCR_RTCSEL_1; /* LSI */
      }
      RCC->BDCR |= RCC_BDCR_RTCEN;          /* enable RTC                           */
      RTC->BKP7R = 0xB007C0DEU;             /* BL_FORCE_DFU_MAGIC                    */
      __DSB();
#endif
    }

    // Stop and De-initialize Timers
    HAL_TIM_Base_DeInit(&htim1);
    HAL_TIM_Base_DeInit(&htim3);
    HAL_TIM_Base_DeInit(&htim12);
    HAL_TIM_Base_DeInit(&htim15);
    HAL_TIM_Base_DeInit(&htim2);

    // De-initialize I2C interfaces
    HAL_I2C_DeInit(&hi2c1);
    HAL_I2C_DeInit(&hi2c2);
    HAL_I2C_DeInit(&hi2c4);

    // De-initialize SPI interfaces
    HAL_SPI_DeInit(&hspi1);
    HAL_SPI_DeInit(&hspi2);
    HAL_SPI_DeInit(&hspi3);
    HAL_SPI_DeInit(&hspi4);

    // De-initialize UART
    HAL_UART_DeInit(&huart4);

    // De-initialize other specific modules
    HAL_RNG_DeInit(&hrng);
    HAL_CRC_DeInit(&hcrc);

    MX_USB_DEVICE_DeInit();
    /* Let the host see the USB disconnect before the reset. 300 ms is longer
     * than the 250 ms watchdog window, so refresh it while waiting: the reset
     * stays a software reset rather than a watchdog one (CFW-01). This runs in
     * the TIM15 interrupt, so it busy-waits; HAL_IWDG_Refresh is one register
     * write. */
    for (uint32_t i = 0U; i < 300U; i++) {
      delay_ms(1);
      watchdog_refresh();
    }
    // Reset the board
    NVIC_SystemReset();

  }

  /* USER CODE END Callback 1 */
}

void Error_Handler(void)
{
  /* USER CODE BEGIN Error_Handler_Debug */
  /* Fatal error (CFW-01, ARCH-82): put the trigger in the safe state, then wait
   * for the independent watchdog to reset the MCU. Also reached from the
   * HardFault, MemManage, BusFault and UsageFault handlers. Interrupts are
   * off, so Trigger_EmergencyStop() writes the timer and GPIO registers
   * directly. The watchdog is never refreshed here, so the reset follows
   * within its 250 ms window.
   * TEC: the TEC DAC sets the ADN8831 temperature setpoint (TEMPSET) and the
   * MCU has no TEC shutdown control, so writing a DAC code here could command
   * full drive. The TEC controller is left regulating at its setpoint. */
  __disable_irq();
  Trigger_EmergencyStop();
  /* Flash blue LED ~500ms on/off to indicate an error state until the reset */
  while (1)
  {
    LED_RGB_SET(LED_BLUE);
    delay_ms(500);
    LED_RGB_SET(LED_NONE);
    delay_ms(500);
  }
  /* USER CODE END Error_Handler_Debug */
}
